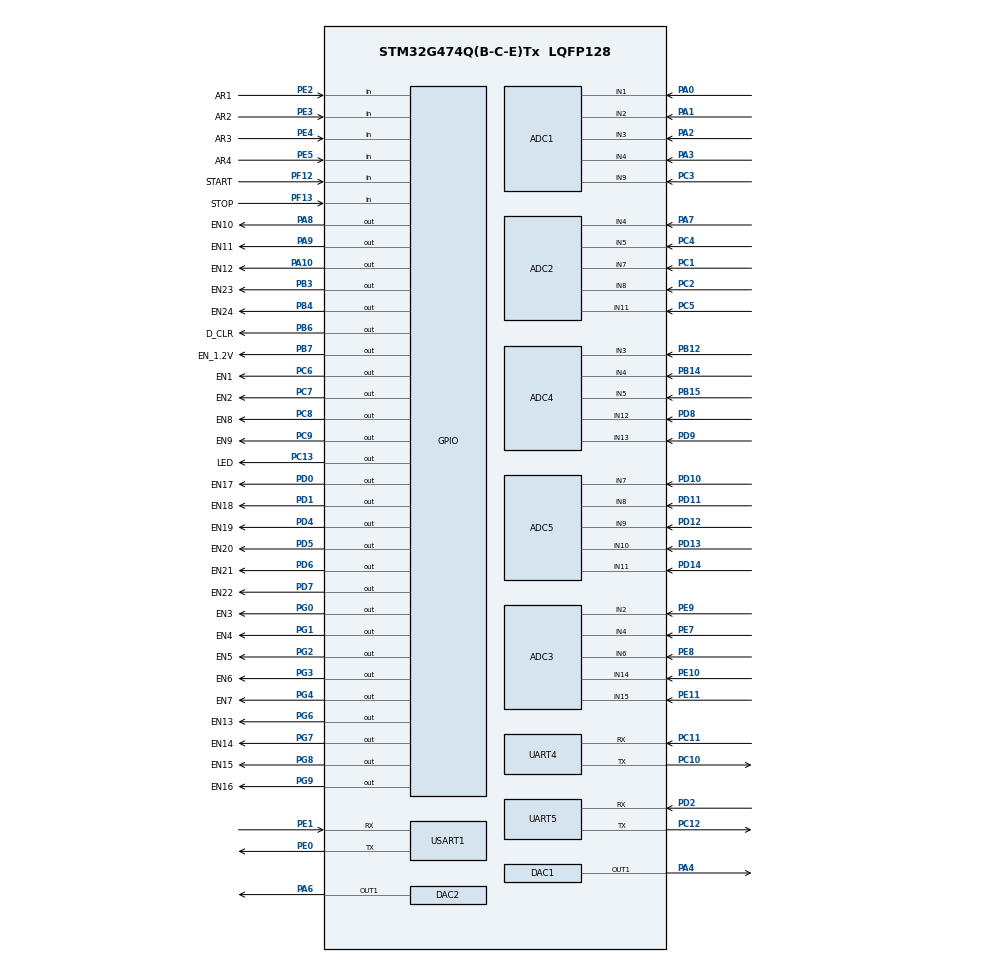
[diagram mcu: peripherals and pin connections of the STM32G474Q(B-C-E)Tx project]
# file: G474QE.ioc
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ADC1.Channel-0\#ChannelRegularConversion=ADC_CHANNEL_9
ADC1.ClockPrescaler=ADC_CLOCK_ASYNC_DIV4
ADC1.NbrOfConversionFlag=1
ADC1.OffsetNumber-0\#ChannelRegularConversion=ADC_OFFSET_NONE
ADC1.Rank-0\#ChannelRegularConversion=1
ADC1.SamplingTime-0\#ChannelRegularConversion=ADC_SAMPLETIME_2CYCLES_5
ADC1.master=1
ADC2.Channel-0\#ChannelRegularConversion=ADC_CHANNEL_4
ADC2.ClockPrescaler=ADC_CLOCK_ASYNC_DIV4
ADC2.NbrOfConversionFlag=1
ADC2.OffsetNumber-0\#ChannelRegularConversion=ADC_OFFSET_NONE
ADC2.Rank-0\#ChannelRegularConversion=1
ADC2.SamplingTime-0\#ChannelRegularConversion=ADC_SAMPLETIME_2CYCLES_5
ADC3.Channel-0\#ChannelRegularConversion=ADC_CHANNEL_4
ADC3.ClockPrescaler=ADC_CLOCK_ASYNC_DIV4
ADC3.NbrOfConversionFlag=1
ADC3.OffsetNumber-0\#ChannelRegularConversion=ADC_OFFSET_NONE
ADC3.Rank-0\#ChannelRegularConversion=1
ADC3.SamplingTime-0\#ChannelRegularConversion=ADC_SAMPLETIME_2CYCLES_5
ADC3.master=1
ADC4.Channel-1\#ChannelRegularConversion=ADC_CHANNEL_5
ADC4.ClockPrescaler=ADC_CLOCK_ASYNC_DIV4
ADC4.NbrOfConversionFlag=1
ADC4.OffsetNumber-1\#ChannelRegularConversion=ADC_OFFSET_NONE
ADC4.Rank-1\#ChannelRegularConversion=1
ADC4.SamplingTime-1\#ChannelRegularConversion=ADC_SAMPLETIME_2CYCLES_5
ADC5.Channel-0\#ChannelRegularConversion=ADC_CHANNEL_10
ADC5.ClockPrescaler=ADC_CLOCK_ASYNC_DIV4
ADC5.NbrOfConversionFlag=1
ADC5.OffsetNumber-0\#ChannelRegularConversion=ADC_OFFSET_NONE
ADC5.Rank-0\#ChannelRegularConversion=1
ADC5.SamplingTime-0\#ChannelRegularConversion=ADC_SAMPLETIME_2CYCLES_5
DAC1.DAC_SampleAndHold-DAC_OUT1=DAC_SAMPLEANDHOLD_DISABLE
Dma.ADC1.0.Direction=DMA_PERIPH_TO_MEMORY
Dma.ADC1.0.EventEnable=DISABLE
Dma.ADC1.0.Instance=DMA1_Channel1
Dma.ADC1.0.MemDataAlignment=DMA_MDATAALIGN_HALFWORD
Dma.ADC1.0.MemInc=DMA_MINC_ENABLE
Dma.ADC1.0.Mode=DMA_NORMAL
Dma.ADC1.0.PeriphDataAlignment=DMA_PDATAALIGN_HALFWORD
Dma.ADC1.0.PeriphInc=DMA_PINC_DISABLE
Dma.ADC1.0.Polarity=HAL_DMAMUX_REQ_GEN_RISING
Dma.ADC1.0.Priority=DMA_PRIORITY_LOW
Dma.ADC1.0.RequestNumber=1
Dma.ADC1.0.SignalID=NONE
Dma.ADC1.0.SyncEnable=DISABLE
Dma.ADC1.0.SyncPolarity=HAL_DMAMUX_SYNC_NO_EVENT
Dma.ADC1.0.SyncRequestNumber=1
Dma.ADC1.0.SyncSignalID=NONE
Dma.ADC2.1.Direction=DMA_PERIPH_TO_MEMORY
Dma.ADC2.1.EventEnable=DISABLE
Dma.ADC2.1.Instance=DMA1_Channel2
Dma.ADC2.1.MemDataAlignment=DMA_MDATAALIGN_HALFWORD
Dma.ADC2.1.MemInc=DMA_MINC_ENABLE
Dma.ADC2.1.Mode=DMA_NORMAL
Dma.ADC2.1.PeriphDataAlignment=DMA_PDATAALIGN_HALFWORD
Dma.ADC2.1.PeriphInc=DMA_PINC_DISABLE
Dma.ADC2.1.Polarity=HAL_DMAMUX_REQ_GEN_RISING
Dma.ADC2.1.Priority=DMA_PRIORITY_LOW
Dma.ADC2.1.RequestNumber=1
Dma.ADC2.1.SignalID=NONE
Dma.ADC2.1.SyncEnable=DISABLE
Dma.ADC2.1.SyncPolarity=HAL_DMAMUX_SYNC_NO_EVENT
Dma.ADC2.1.SyncRequestNumber=1
Dma.ADC2.1.SyncSignalID=NONE
Dma.ADC3.2.Direction=DMA_PERIPH_TO_MEMORY
Dma.ADC3.2.EventEnable=DISABLE
Dma.ADC3.2.Instance=DMA1_Channel3
Dma.ADC3.2.MemDataAlignment=DMA_MDATAALIGN_HALFWORD
Dma.ADC3.2.MemInc=DMA_MINC_ENABLE
Dma.ADC3.2.Mode=DMA_NORMAL
Dma.ADC3.2.PeriphDataAlignment=DMA_PDATAALIGN_HALFWORD
Dma.ADC3.2.PeriphInc=DMA_PINC_DISABLE
Dma.ADC3.2.Polarity=HAL_DMAMUX_REQ_GEN_RISING
Dma.ADC3.2.Priority=DMA_PRIORITY_LOW
Dma.ADC3.2.RequestNumber=1
Dma.ADC3.2.SignalID=NONE
Dma.ADC3.2.SyncEnable=DISABLE
Dma.ADC3.2.SyncPolarity=HAL_DMAMUX_SYNC_NO_EVENT
Dma.ADC3.2.SyncRequestNumber=1
Dma.ADC3.2.SyncSignalID=NONE
Dma.ADC4.3.Direction=DMA_PERIPH_TO_MEMORY
Dma.ADC4.3.EventEnable=DISABLE
Dma.ADC4.3.Instance=DMA1_Channel4
Dma.ADC4.3.MemDataAlignment=DMA_MDATAALIGN_HALFWORD
Dma.ADC4.3.MemInc=DMA_MINC_ENABLE
Dma.ADC4.3.Mode=DMA_NORMAL
Dma.ADC4.3.PeriphDataAlignment=DMA_PDATAALIGN_HALFWORD
Dma.ADC4.3.PeriphInc=DMA_PINC_DISABLE
Dma.ADC4.3.Polarity=HAL_DMAMUX_REQ_GEN_RISING
Dma.ADC4.3.Priority=DMA_PRIORITY_LOW
Dma.ADC4.3.RequestNumber=1
Dma.ADC4.3.SignalID=NONE
Dma.ADC4.3.SyncEnable=DISABLE
Dma.ADC4.3.SyncPolarity=HAL_DMAMUX_SYNC_NO_EVENT
Dma.ADC4.3.SyncRequestNumber=1
Dma.ADC4.3.SyncSignalID=NONE
Dma.ADC5.4.Direction=DMA_PERIPH_TO_MEMORY
Dma.ADC5.4.EventEnable=DISABLE
Dma.ADC5.4.Instance=DMA1_Channel5
Dma.ADC5.4.MemDataAlignment=DMA_MDATAALIGN_HALFWORD
Dma.ADC5.4.MemInc=DMA_MINC_ENABLE
Dma.ADC5.4.Mode=DMA_NORMAL
Dma.ADC5.4.PeriphDataAlignment=DMA_PDATAALIGN_HALFWORD
Dma.ADC5.4.PeriphInc=DMA_PINC_DISABLE
Dma.ADC5.4.Polarity=HAL_DMAMUX_REQ_GEN_RISING
Dma.ADC5.4.Priority=DMA_PRIORITY_LOW
Dma.ADC5.4.RequestNumber=1
Dma.ADC5.4.SignalID=NONE
Dma.ADC5.4.SyncEnable=DISABLE
Dma.ADC5.4.SyncPolarity=HAL_DMAMUX_SYNC_NO_EVENT
Dma.ADC5.4.SyncRequestNumber=1
Dma.ADC5.4.SyncSignalID=NONE
Dma.Request0=ADC1
Dma.Request1=ADC2
Dma.Request2=ADC3
Dma.Request3=ADC4
Dma.Request4=ADC5
IWDG.Prescaler=IWDG_PRESCALER_64
Mcu.Family=STM32G4
Mcu.Name=STM32G474Q(B-C-E)Tx
Mcu.Package=LQFP128
NVIC.DMA1_Channel1_IRQn=true\:0\:0\:true\:false\:true\:false\:true\:true
NVIC.DMA1_Channel2_IRQn=true\:0\:0\:false\:false\:true\:false\:true\:true
NVIC.DMA1_Channel3_IRQn=true\:0\:0\:false\:false\:true\:false\:true\:true
NVIC.DMA1_Channel4_IRQn=true\:0\:0\:false\:false\:true\:false\:true\:true
NVIC.DMA1_Channel5_IRQn=true\:0\:0\:false\:false\:true\:false\:true\:true
NVIC.PriorityGroup=NVIC_PRIORITYGROUP_4
NVIC.UART4_IRQn=true\:9\:0\:true\:false\:true\:true\:true\:true
NVIC.UART5_IRQn=true\:8\:0\:true\:false\:true\:true\:true\:true
PA0.Mode=IN1-Single-Ended
PA0.Signal=ADC1_IN1
PA1.Mode=IN2-Single-Ended
PA1.Signal=ADC1_IN2
PA10.GPIO_Label=EN12
PA10.Signal=GPIO_Output
PA13.Mode=Serial_Wire
PA13.Signal=SYS_JTMS-SWDIO
PA14.Mode=Serial_Wire
PA14.Signal=SYS_JTCK-SWCLK
PA2.Mode=IN3-Single-Ended
PA2.Signal=ADC1_IN3
PA3.Mode=IN4-Single-Ended
PA3.Signal=ADC1_IN4
PA4.Signal=COMP_DAC11_group
PA6.Signal=COMP_DAC21_group
PA7.Mode=IN4-Single-Ended
PA7.Signal=ADC2_IN4
PA8.GPIO_Label=EN10
PA8.Signal=GPIO_Output
PA9.GPIO_Label=EN11
PA9.Signal=GPIO_Output
PB12.Mode=IN3-Single-Ended
PB12.Signal=ADC4_IN3
PB14.Mode=IN4-Single-Ended
PB14.Signal=ADC4_IN4
PB15.Mode=IN5-Single-Ended
PB15.Signal=ADC4_IN5
PB3.GPIO_Label=EN23
PB3.Signal=GPIO_Output
PB4.GPIO_Label=EN24
PB4.Signal=GPIO_Output
PB6.GPIO_Label=D_CLR
PB6.Signal=GPIO_Output
PB7.GPIO_Label=EN_1.2V
PB7.Signal=GPIO_Output
PC1.Mode=IN7-Single-Ended
PC1.Signal=ADC2_IN7
PC10.Mode=Asynchronous
PC10.Signal=UART4_TX
PC11.Mode=Asynchronous
PC11.Signal=UART4_RX
PC12.Mode=Asynchronous
PC12.Signal=UART5_TX
PC13.GPIO_Label=LED
PC13.Signal=GPIO_Output
PC2.Mode=IN8-Single-Ended
PC2.Signal=ADC2_IN8
PC3.Mode=IN9-Single-Ended
PC3.Signal=ADC1_IN9
PC4.Mode=IN5-Single-Ended
PC4.Signal=ADC2_IN5
PC5.Mode=IN11-Single-Ended
PC5.Signal=ADC2_IN11
PC6.GPIO_Label=EN1
PC6.Signal=GPIO_Output
PC7.GPIO_Label=EN2
PC7.Signal=GPIO_Output
PC8.GPIO_Label=EN8
PC8.Signal=GPIO_Output
PC9.GPIO_Label=EN9
PC9.Signal=GPIO_Output
PD0.GPIO_Label=EN17
PD0.Signal=GPIO_Output
PD1.GPIO_Label=EN18
PD1.Signal=GPIO_Output
PD10.Mode=IN7-Single-Ended
PD10.Signal=ADC5_IN7
PD11.Mode=IN8-Single-Ended
PD11.Signal=ADC5_IN8
PD12.Mode=IN9-Single-Ended
PD12.Signal=ADC5_IN9
PD13.Mode=IN10-Single-Ended
PD13.Signal=ADC5_IN10
PD14.Mode=IN11-Single-Ended
PD14.Signal=ADC5_IN11
PD2.Mode=Asynchronous
PD2.Signal=UART5_RX
PD4.GPIO_Label=EN19
PD4.Signal=GPIO_Output
PD5.GPIO_Label=EN20
PD5.Signal=GPIO_Output
PD6.GPIO_Label=EN21
PD6.Signal=GPIO_Output
PD7.GPIO_Label=EN22
PD7.Signal=GPIO_Output
PD8.Mode=IN12-Single-Ended
PD8.Signal=ADC4_IN12
PD9.Mode=IN13-Single-Ended
PD9.Signal=ADC4_IN13
PE0.Mode=Asynchronous
PE0.Signal=USART1_TX
PE1.Mode=Asynchronous
PE1.Signal=USART1_RX
PE10.Mode=IN14-Single-Ended
PE10.Signal=ADC3_IN14
PE11.Mode=IN15-Single-Ended
PE11.Signal=ADC3_IN15
PE2.GPIO_Label=AR1
PE2.GPIO_Mode=GPIO_MODE_INPUT
PE2.GPIO_PuPd=GPIO_PULLUP
PE2.Signal=GPIO_Input
PE3.GPIO_Label=AR2
PE3.GPIO_Mode=GPIO_MODE_INPUT
PE3.GPIO_PuPd=GPIO_PULLUP
PE3.Signal=GPIO_Input
PE4.GPIO_Label=AR3
PE4.GPIO_Mode=GPIO_MODE_INPUT
PE4.GPIO_PuPd=GPIO_PULLUP
PE4.Signal=GPIO_Input
PE5.GPIO_Label=AR4
PE5.GPIO_Mode=GPIO_MODE_INPUT
PE5.GPIO_PuPd=GPIO_PULLUP
PE5.Signal=GPIO_Input
PE7.Mode=IN4-Single-Ended
PE7.Signal=ADC3_IN4
PE8.Mode=IN6-Single-Ended
PE8.Signal=ADC3_IN6
PE9.Mode=IN2-Single-Ended
PE9.Signal=ADC3_IN2
PF0-OSC_IN.Mode=HSE-External-Oscillator
PF0-OSC_IN.Signal=RCC_OSC_IN
PF1-OSC_OUT.Mode=HSE-External-Oscillator
PF1-OSC_OUT.Signal=RCC_OSC_OUT
PF12.GPIO_Label=START
PF12.GPIO_PuPd=GPIO_PULLUP
PF12.Signal=GPIO_Input
PF13.GPIO_Label=STOP
PF13.GPIO_PuPd=GPIO_PULLUP
PF13.Signal=GPIO_Input
PG0.GPIO_Label=EN3
PG0.Signal=GPIO_Output
PG1.GPIO_Label=EN4
PG1.Signal=GPIO_Output
PG2.GPIO_Label=EN5
PG2.Signal=GPIO_Output
PG3.GPIO_Label=EN6
PG3.Signal=GPIO_Output
PG4.GPIO_Label=EN7
PG4.Signal=GPIO_Output
PG6.GPIO_Label=EN13
PG6.PinState=GPIO_PIN_RESET
PG6.Signal=GPIO_Output
PG7.GPIO_Label=EN14
PG7.PinState=GPIO_PIN_RESET
PG7.Signal=GPIO_Output
PG8.GPIO_Label=EN15
PG8.PinState=GPIO_PIN_RESET
PG8.Signal=GPIO_Output
PG9.GPIO_Label=EN16
PG9.Signal=GPIO_Output
ProjectManager.HeapSize=0x200
ProjectManager.StackSize=0x400
ProjectManager.TargetToolchain=MDK-ARM V5.32
RCC.ADC12Freq_Value=168000000
RCC.ADC345Freq_Value=168000000
RCC.AHBFreq_Value=168000000
RCC.APB1Freq_Value=168000000
RCC.APB1TimFreq_Value=168000000
RCC.APB2Freq_Value=168000000
RCC.APB2TimFreq_Value=168000000
RCC.CortexFreq_Value=168000000
RCC.DATA_CACHE_ENABLE=0
RCC.EXTERNAL_CLOCK_VALUE=12288000
RCC.HCLKFreq_Value=168000000
RCC.HSE_VALUE=16000000
RCC.HSI48_VALUE=48000000
RCC.HSI_VALUE=16000000
RCC.INSTRUCTION_CACHE_ENABLE=0
RCC.LSE_VALUE=32768
RCC.PLLM=RCC_PLLM_DIV2
RCC.PLLN=42
RCC.PLLSourceVirtual=RCC_PLLSOURCE_HSE
RCC.SYSCLKFreq_VALUE=168000000
RCC.SYSCLKSource=RCC_SYSCLKSOURCE_PLLCLK
RCC.USBFreq_Value=168000000
RCC.VCOOutputFreq_Value=336000000
SH.COMP_DAC11_group.0=DAC1_OUT1,DAC_OUT1
SH.COMP_DAC21_group.0=DAC2_OUT1,DAC_OUT1
TIM1.Prescaler=1680-1
USART1.VirtualMode-Asynchronous=VM_ASYNC
VP_IWDG_VS_IWDG.Mode=IWDG_Activate
VP_SYS_VS_DBSignals.Mode=DisableDeadBatterySignals
VP_TIM1_VS_ClockSourceINT.Mode=Internal
VP_TIM2_VS_ClockSourceINT.Mode=Internal
VP_TIM3_VS_ClockSourceINT.Mode=Internal
board=custom

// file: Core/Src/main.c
/* USER CODE BEGIN Header */
/**
  ******************************************************************************
  * @file           : main.c
  * @brief          : Main program body
  ******************************************************************************
  * @attention
  *
  * Copyright (c) 2026 STMicroelectronics.
  * All rights reserved.
  *
  * This software is licensed under terms that can be found in the LICENSE file
  * in the root directory of this software component.
  * If no LICENSE file comes with this software, it is provided AS-IS.
  *
  ******************************************************************************
  */
/* USER CODE END Header */
#include "main.h"

/* USER CODE BEGIN Includes */
#define 	ADC_SAMPLE_TIME						LL_ADC_SAMPLINGTIME_24CYCLES_5
/* USER CODE END Includes */

void SystemClock_Config(void);
static void MX_GPIO_Init(void);
static void MX_DMA_Init(void);
static void MX_ADC1_Init(void);
static void MX_ADC2_Init(void);
static void MX_ADC3_Init(void);
static void MX_ADC4_Init(void);
static void MX_ADC5_Init(void);
static void MX_DAC1_Init(void);
static void MX_DAC2_Init(void);
static void MX_USART1_UART_Init(void);
static void MX_UART4_Init(void);
static void MX_UART5_Init(void);
static void MX_TIM1_Init(void);
static void MX_TIM2_Init(void);
static void MX_TIM3_Init(void);
static void MX_IWDG_Init(void);
/* USER CODE BEGIN PFP */
void Activate_ADC(ADC_TypeDef *ADCx);

/* USER CODE END PFP */

int main(void)
{

  /* MCU Configuration--------------------------------------------------------*/

  /* Reset of all peripherals, Initializes the Flash interface and the Systick. */
  LL_APB2_GRP1_EnableClock(LL_APB2_GRP1_PERIPH_SYSCFG);
  LL_APB1_GRP1_EnableClock(LL_APB1_GRP1_PERIPH_PWR);

  /* System interrupt init*/
  NVIC_SetPriorityGrouping(NVIC_PRIORITYGROUP_4);

  /* SysTick_IRQn interrupt configuration */
  NVIC_SetPriority(SysTick_IRQn, NVIC_EncodePriority(NVIC_GetPriorityGrouping(),10, 0));

  /** Disable the internal Pull-Up in Dead Battery pins of UCPD peripheral
  */
  LL_PWR_DisableUCPDDeadBattery();

  /* Configure the system clock */
  SystemClock_Config();

  /* USER CODE BEGIN SysInit */
	initUartFifo();

  /* USER CODE END SysInit */

  /* Initialize all configured peripherals */
  MX_GPIO_Init();
  MX_DMA_Init();
  MX_ADC1_Init();
  MX_ADC2_Init();
  MX_ADC3_Init();
  MX_ADC4_Init();
  MX_ADC5_Init();
  MX_DAC1_Init();
  MX_DAC2_Init();
  MX_USART1_UART_Init();
  MX_UART4_Init();
  MX_UART5_Init();
  MX_TIM1_Init();
  MX_TIM2_Init();
  MX_TIM3_Init();
  //MX_IWDG_Init();
  /* USER CODE BEGIN 2 */
	readMyAddr();
 Activate_ADC(ADC1);
 Activate_ADC(ADC2);
 Activate_ADC(ADC3);
 Activate_ADC(ADC4);
 Activate_ADC(ADC5);
 initADC();

  Trace_Print(" system start \r\n");
  /* USER CODE END 2 */

  /* Infinite loop */
  /* USER CODE BEGIN WHILE */
  while (1)
  {

 	  cleanMain();
		debugFunc();
   // testuart4Send();
		//testuart5Send();
    /* USER CODE END WHILE */

  }
}

void SystemClock_Config(void)
{
  LL_FLASH_SetLatency(LL_FLASH_LATENCY_4);
  while(LL_FLASH_GetLatency() != LL_FLASH_LATENCY_4)
  {
  }
  LL_PWR_EnableRange1BoostMode();
  LL_RCC_HSE_Enable();
   /* Wait till HSE is ready */
  while(LL_RCC_HSE_IsReady() != 1)
  {
  }

  LL_RCC_LSI_Enable();
   /* Wait till LSI is ready */
  while(LL_RCC_LSI_IsReady() != 1)
  {
  }

  LL_RCC_PLL_ConfigDomain_SYS(LL_RCC_PLLSOURCE_HSE, LL_RCC_PLLM_DIV_2, 42, LL_RCC_PLLR_DIV_2);
  LL_RCC_PLL_EnableDomain_SYS();
  LL_RCC_PLL_Enable();
   /* Wait till PLL is ready */
  while(LL_RCC_PLL_IsReady() != 1)
  {
  }

  LL_RCC_SetSysClkSource(LL_RCC_SYS_CLKSOURCE_PLL);
  LL_RCC_SetAHBPrescaler(LL_RCC_SYSCLK_DIV_2);
   /* Wait till System clock is ready */
  while(LL_RCC_GetSysClkSource() != LL_RCC_SYS_CLKSOURCE_STATUS_PLL)
  {
  }

  /* Insure 1us transition state at intermediate medium speed clock*/
  for (__IO uint32_t i = (170 >> 1); i !=0; i--);

  /* Set AHB prescaler*/
  LL_RCC_SetAHBPrescaler(LL_RCC_SYSCLK_DIV_1);
  LL_RCC_SetAPB1Prescaler(LL_RCC_APB1_DIV_1);
  LL_RCC_SetAPB2Prescaler(LL_RCC_APB2_DIV_1);

  LL_Init1msTick(168000000);

  LL_SetSystemCoreClock(168000000);
}

static void MX_ADC1_Init(void)
{

  LL_ADC_InitTypeDef ADC_InitStruct = {0};
  LL_ADC_REG_InitTypeDef ADC_REG_InitStruct = {0};
  LL_ADC_CommonInitTypeDef ADC_CommonInitStruct = {0};

  LL_GPIO_InitTypeDef GPIO_InitStruct = {0};

  LL_RCC_SetADCClockSource(LL_RCC_ADC12_CLKSOURCE_SYSCLK);

  /* Peripheral clock enable */
  LL_AHB2_GRP1_EnableClock(LL_AHB2_GRP1_PERIPH_ADC12);

  LL_AHB2_GRP1_EnableClock(LL_AHB2_GRP1_PERIPH_GPIOC);
  LL_AHB2_GRP1_EnableClock(LL_AHB2_GRP1_PERIPH_GPIOA);
  /**ADC1 GPIO Configuration
  PC3   ------> ADC1_IN9
  PA0   ------> ADC1_IN1
  PA1   ------> ADC1_IN2
  PA2   ------> ADC1_IN3
  PA3   ------> ADC1_IN4
  */
  GPIO_InitStruct.Pin = LL_GPIO_PIN_3;
  GPIO_InitStruct.Mode = LL_GPIO_MODE_ANALOG;
  GPIO_InitStruct.Pull = LL_GPIO_PULL_NO;
  LL_GPIO_Init(GPIOC, &GPIO_InitStruct);

  GPIO_InitStruct.Pin = LL_GPIO_PIN_0;
  GPIO_InitStruct.Mode = LL_GPIO_MODE_ANALOG;
  GPIO_InitStruct.Pull = LL_GPIO_PULL_NO;
  LL_GPIO_Init(GPIOA, &GPIO_InitStruct);

  GPIO_InitStruct.Pin = LL_GPIO_PIN_1;
  GPIO_InitStruct.Mode = LL_GPIO_MODE_ANALOG;
  GPIO_InitStruct.Pull = LL_GPIO_PULL_NO;
  LL_GPIO_Init(GPIOA, &GPIO_InitStruct);

  GPIO_InitStruct.Pin = LL_GPIO_PIN_2;
  GPIO_InitStruct.Mode = LL_GPIO_MODE_ANALOG;
  GPIO_InitStruct.Pull = LL_GPIO_PULL_NO;
  LL_GPIO_Init(GPIOA, &GPIO_InitStruct);

  GPIO_InitStruct.Pin = LL_GPIO_PIN_3;
  GPIO_InitStruct.Mode = LL_GPIO_MODE_ANALOG;
  GPIO_InitStruct.Pull = LL_GPIO_PULL_NO;
  LL_GPIO_Init(GPIOA, &GPIO_InitStruct);

  /* ADC1 DMA Init */

  /* ADC1 Init */
  LL_DMA_SetPeriphRequest(DMA1, LL_DMA_CHANNEL_1, LL_DMAMUX_REQ_ADC1);

  LL_DMA_SetDataTransferDirection(DMA1, LL_DMA_CHANNEL_1, LL_DMA_DIRECTION_PERIPH_TO_MEMORY);

  LL_DMA_SetChannelPriorityLevel(DMA1, LL_DMA_CHANNEL_1, LL_DMA_PRIORITY_LOW);

  LL_DMA_SetMode(DMA1, LL_DMA_CHANNEL_1, LL_DMA_MODE_NORMAL);

  LL_DMA_SetPeriphIncMode(DMA1, LL_DMA_CHANNEL_1, LL_DMA_PERIPH_NOINCREMENT);

  LL_DMA_SetMemoryIncMode(DMA1, LL_DMA_CHANNEL_1, LL_DMA_MEMORY_INCREMENT);

  LL_DMA_SetPeriphSize(DMA1, LL_DMA_CHANNEL_1, LL_DMA_PDATAALIGN_HALFWORD);

  LL_DMA_SetMemorySize(DMA1, LL_DMA_CHANNEL_1, LL_DMA_MDATAALIGN_HALFWORD);

  /** Common config
  */
  ADC_InitStruct.Resolution = LL_ADC_RESOLUTION_12B;
  ADC_InitStruct.DataAlignment = LL_ADC_DATA_ALIGN_RIGHT;
  ADC_InitStruct.LowPowerMode = LL_ADC_LP_MODE_NONE;
  LL_ADC_Init(ADC1, &ADC_InitStruct);
  ADC_REG_InitStruct.TriggerSource = LL_ADC_REG_TRIG_SOFTWARE;
  ADC_REG_InitStruct.SequencerLength = LL_ADC_REG_SEQ_SCAN_ENABLE_5RANKS;
  ADC_REG_InitStruct.SequencerDiscont = LL_ADC_REG_SEQ_DISCONT_DISABLE;
  ADC_REG_InitStruct.ContinuousMode = LL_ADC_REG_CONV_CONTINUOUS;
  ADC_REG_InitStruct.DMATransfer = LL_ADC_REG_DMA_TRANSFER_UNLIMITED;
  ADC_REG_InitStruct.Overrun = LL_ADC_REG_OVR_DATA_PRESERVED;
  LL_ADC_REG_Init(ADC1, &ADC_REG_InitStruct);
  LL_ADC_SetGainCompensation(ADC1, 0);
  LL_ADC_SetOverSamplingScope(ADC1, LL_ADC_OVS_DISABLE);
  ADC_CommonInitStruct.CommonClock = LL_ADC_CLOCK_ASYNC_DIV16;
  ADC_CommonInitStruct.Multimode = LL_ADC_MULTI_INDEPENDENT;
  LL_ADC_CommonInit(__LL_ADC_COMMON_INSTANCE(ADC1), &ADC_CommonInitStruct);

  /* Disable ADC deep power down (enabled by default after reset state) */
  LL_ADC_DisableDeepPowerDown(ADC1);
  /* Enable ADC internal voltage regulator */
  LL_ADC_EnableInternalRegulator(ADC1);
  /* Delay for ADC internal voltage regulator stabilization. */
  /* Compute number of CPU cycles to wait for, from delay in us. */
  /* Note: Variable divided by 2 to compensate partially */
  /* CPU processing cycles (depends on compilation optimization). */
  /* Note: If system core clock frequency is below 200kHz, wait time */
  /* is only a few CPU processing cycles. */
  uint32_t wait_loop_index;
  wait_loop_index = ((LL_ADC_DELAY_INTERNAL_REGUL_STAB_US * (SystemCoreClock / (100000 * 2))) / 10);
  while(wait_loop_index != 0)
  {
    wait_loop_index--;
  }

  /** Configure Regular Channel
  */
  /* USER CODE BEGIN ADC1_Init 2 */

	// 18 -22
  LL_ADC_REG_SetSequencerRanks(ADC1, LL_ADC_REG_RANK_1, LL_ADC_CHANNEL_4);
  LL_ADC_SetChannelSamplingTime(ADC1, LL_ADC_CHANNEL_4, ADC_SAMPLE_TIME);
  LL_ADC_SetChannelSingleDiff(ADC1, LL_ADC_CHANNEL_4, LL_ADC_SINGLE_ENDED);

  LL_ADC_REG_SetSequencerRanks(ADC1, LL_ADC_REG_RANK_2, LL_ADC_CHANNEL_3);
  LL_ADC_SetChannelSamplingTime(ADC1, LL_ADC_CHANNEL_3, ADC_SAMPLE_TIME);
  LL_ADC_SetChannelSingleDiff(ADC1, LL_ADC_CHANNEL_3, LL_ADC_SINGLE_ENDED);

  LL_ADC_REG_SetSequencerRanks(ADC1, LL_ADC_REG_RANK_3, LL_ADC_CHANNEL_2);
  LL_ADC_SetChannelSamplingTime(ADC1, LL_ADC_CHANNEL_2, ADC_SAMPLE_TIME);
  LL_ADC_SetChannelSingleDiff(ADC1, LL_ADC_CHANNEL_2, LL_ADC_SINGLE_ENDED);

  LL_ADC_REG_SetSequencerRanks(ADC1, LL_ADC_REG_RANK_4, LL_ADC_CHANNEL_1);
  LL_ADC_SetChannelSamplingTime(ADC1, LL_ADC_CHANNEL_1, ADC_SAMPLE_TIME);
  LL_ADC_SetChannelSingleDiff(ADC1, LL_ADC_CHANNEL_1, LL_ADC_SINGLE_ENDED);

  LL_ADC_REG_SetSequencerRanks(ADC1, LL_ADC_REG_RANK_5, LL_ADC_CHANNEL_9);
  LL_ADC_SetChannelSamplingTime(ADC1, LL_ADC_CHANNEL_9, ADC_SAMPLE_TIME);
  LL_ADC_SetChannelSingleDiff(ADC1, LL_ADC_CHANNEL_9, LL_ADC_SINGLE_ENDED);

	//LL_ADC_REG_SetSequencerLength(ADC1,LL_ADC_REG_SEQ_SCAN_ENABLE_5RANKS);
	//LL_ADC_REG_SetContinuousMode

  /* USER CODE END ADC1_Init 2 */

}

static void MX_ADC2_Init(void)
{

  LL_ADC_InitTypeDef ADC_InitStruct = {0};
  LL_ADC_REG_InitTypeDef ADC_REG_InitStruct = {0};

  LL_GPIO_InitTypeDef GPIO_InitStruct = {0};

  LL_RCC_SetADCClockSource(LL_RCC_ADC12_CLKSOURCE_SYSCLK);

  /* Peripheral clock enable */
  LL_AHB2_GRP1_EnableClock(LL_AHB2_GRP1_PERIPH_ADC12);

  LL_AHB2_GRP1_EnableClock(LL_AHB2_GRP1_PERIPH_GPIOC);
  LL_AHB2_GRP1_EnableClock(LL_AHB2_GRP1_PERIPH_GPIOA);
  /**ADC2 GPIO Configuration
  PC1   ------> ADC2_IN7
  PC2   ------> ADC2_IN8
  PA7   ------> ADC2_IN4
  PC4   ------> ADC2_IN5
  PC5   ------> ADC2_IN11
  */
  GPIO_InitStruct.Pin = LL_GPIO_PIN_1;
  GPIO_InitStruct.Mode = LL_GPIO_MODE_ANALOG;
  GPIO_InitStruct.Pull = LL_GPIO_PULL_NO;
  LL_GPIO_Init(GPIOC, &GPIO_InitStruct);

  GPIO_InitStruct.Pin = LL_GPIO_PIN_2;
  GPIO_InitStruct.Mode = LL_GPIO_MODE_ANALOG;
  GPIO_InitStruct.Pull = LL_GPIO_PULL_NO;
  LL_GPIO_Init(GPIOC, &GPIO_InitStruct);

  GPIO_InitStruct.Pin = LL_GPIO_PIN_7;
  GPIO_InitStruct.Mode = LL_GPIO_MODE_ANALOG;
  GPIO_InitStruct.Pull = LL_GPIO_PULL_NO;
  LL_GPIO_Init(GPIOA, &GPIO_InitStruct);

  GPIO_InitStruct.Pin = LL_GPIO_PIN_4;
  GPIO_InitStruct.Mode = LL_GPIO_MODE_ANALOG;
  GPIO_InitStruct.Pull = LL_GPIO_PULL_NO;
  LL_GPIO_Init(GPIOC, &GPIO_InitStruct);

  GPIO_InitStruct.Pin = LL_GPIO_PIN_5;
  GPIO_InitStruct.Mode = LL_GPIO_MODE_ANALOG;
  GPIO_InitStruct.Pull = LL_GPIO_PULL_NO;
  LL_GPIO_Init(GPIOC, &GPIO_InitStruct);

  /* ADC2 DMA Init */

  /* ADC2 Init */
  LL_DMA_SetPeriphRequest(DMA1, LL_DMA_CHANNEL_2, LL_DMAMUX_REQ_ADC2);

  LL_DMA_SetDataTransferDirection(DMA1, LL_DMA_CHANNEL_2, LL_DMA_DIRECTION_PERIPH_TO_MEMORY);

  LL_DMA_SetChannelPriorityLevel(DMA1, LL_DMA_CHANNEL_2, LL_DMA_PRIORITY_LOW);

  LL_DMA_SetMode(DMA1, LL_DMA_CHANNEL_2, LL_DMA_MODE_NORMAL);

  LL_DMA_SetPeriphIncMode(DMA1, LL_DMA_CHANNEL_2, LL_DMA_PERIPH_NOINCREMENT);

  LL_DMA_SetMemoryIncMode(DMA1, LL_DMA_CHANNEL_2, LL_DMA_MEMORY_INCREMENT);

  LL_DMA_SetPeriphSize(DMA1, LL_DMA_CHANNEL_2, LL_DMA_PDATAALIGN_HALFWORD);

  LL_DMA_SetMemorySize(DMA1, LL_DMA_CHANNEL_2, LL_DMA_MDATAALIGN_HALFWORD);

  /** Common config
  */
  ADC_InitStruct.Resolution = LL_ADC_RESOLUTION_12B;
  ADC_InitStruct.DataAlignment = LL_ADC_DATA_ALIGN_RIGHT;
  ADC_InitStruct.LowPowerMode = LL_ADC_LP_MODE_NONE;
  LL_ADC_Init(ADC2, &ADC_InitStruct);
  ADC_REG_InitStruct.TriggerSource = LL_ADC_REG_TRIG_SOFTWARE;
  ADC_REG_InitStruct.SequencerLength = LL_ADC_REG_SEQ_SCAN_ENABLE_5RANKS;
  ADC_REG_InitStruct.SequencerDiscont = LL_ADC_REG_SEQ_DISCONT_DISABLE;
  ADC_REG_InitStruct.ContinuousMode = LL_ADC_REG_CONV_CONTINUOUS;
  ADC_REG_InitStruct.DMATransfer = LL_ADC_REG_DMA_TRANSFER_UNLIMITED;
  ADC_REG_InitStruct.Overrun = LL_ADC_REG_OVR_DATA_PRESERVED;
  LL_ADC_REG_Init(ADC2, &ADC_REG_InitStruct);
  LL_ADC_SetGainCompensation(ADC2, 0);
  LL_ADC_SetOverSamplingScope(ADC2, LL_ADC_OVS_DISABLE);

  /* Disable ADC deep power down (enabled by default after reset state) */
  LL_ADC_DisableDeepPowerDown(ADC2);
  /* Enable ADC internal voltage regulator */
  LL_ADC_EnableInternalRegulator(ADC2);
  /* Delay for ADC internal voltage regulator stabilization. */
  /* Compute number of CPU cycles to wait for, from delay in us. */
  /* Note: Variable divided by 2 to compensate partially */
  /* CPU processing cycles (depends on compilation optimization). */
  /* Note: If system core clock frequency is below 200kHz, wait time */
  /* is only a few CPU processing cycles. */
  uint32_t wait_loop_index;
  wait_loop_index = ((LL_ADC_DELAY_INTERNAL_REGUL_STAB_US * (SystemCoreClock / (100000 * 2))) / 10);
  while(wait_loop_index != 0)
  {
    wait_loop_index--;
  }

  /** Configure Regular Channel
  */

  /* USER CODE BEGIN ADC2_Init 2 */
	// 15-17,23,24
  LL_ADC_REG_SetSequencerRanks(ADC2, LL_ADC_REG_RANK_1, LL_ADC_CHANNEL_11);
  LL_ADC_SetChannelSamplingTime(ADC2, LL_ADC_CHANNEL_11, ADC_SAMPLE_TIME);
  LL_ADC_SetChannelSingleDiff(ADC2, LL_ADC_CHANNEL_11, LL_ADC_SINGLE_ENDED);

  LL_ADC_REG_SetSequencerRanks(ADC2, LL_ADC_REG_RANK_2, LL_ADC_CHANNEL_5);
  LL_ADC_SetChannelSamplingTime(ADC2, LL_ADC_CHANNEL_5, ADC_SAMPLE_TIME);
  LL_ADC_SetChannelSingleDiff(ADC2, LL_ADC_CHANNEL_5, LL_ADC_SINGLE_ENDED);

  LL_ADC_REG_SetSequencerRanks(ADC2, LL_ADC_REG_RANK_3, LL_ADC_CHANNEL_4);
  LL_ADC_SetChannelSamplingTime(ADC2, LL_ADC_CHANNEL_4, ADC_SAMPLE_TIME);
  LL_ADC_SetChannelSingleDiff(ADC2, LL_ADC_CHANNEL_4, LL_ADC_SINGLE_ENDED);

	LL_ADC_REG_SetSequencerRanks(ADC2, LL_ADC_REG_RANK_4, LL_ADC_CHANNEL_8);
  LL_ADC_SetChannelSamplingTime(ADC2, LL_ADC_CHANNEL_8, ADC_SAMPLE_TIME);
  LL_ADC_SetChannelSingleDiff(ADC2, LL_ADC_CHANNEL_8, LL_ADC_SINGLE_ENDED);

	LL_ADC_REG_SetSequencerRanks(ADC2, LL_ADC_REG_RANK_5, LL_ADC_CHANNEL_7);
  LL_ADC_SetChannelSamplingTime(ADC2, LL_ADC_CHANNEL_7, ADC_SAMPLE_TIME);
  LL_ADC_SetChannelSingleDiff(ADC2, LL_ADC_CHANNEL_7, LL_ADC_SINGLE_ENDED);

	//LL_ADC_REG_SetSequencerLength(ADC2,LL_ADC_REG_SEQ_SCAN_ENABLE_5RANKS);

  /* USER CODE END ADC2_Init 2 */

}

static void MX_ADC3_Init(void)
{

  LL_ADC_InitTypeDef ADC_InitStruct = {0};
  LL_ADC_REG_InitTypeDef ADC_REG_InitStruct = {0};
  LL_ADC_CommonInitTypeDef ADC_CommonInitStruct = {0};

  LL_GPIO_InitTypeDef GPIO_InitStruct = {0};

  LL_RCC_SetADCClockSource(LL_RCC_ADC345_CLKSOURCE_SYSCLK);

  /* Peripheral clock enable */
  LL_AHB2_GRP1_EnableClock(LL_AHB2_GRP1_PERIPH_ADC345);

  LL_AHB2_GRP1_EnableClock(LL_AHB2_GRP1_PERIPH_GPIOE);
  /**ADC3 GPIO Configuration
  PE7   ------> ADC3_IN4
  PE8   ------> ADC3_IN6
  PE9   ------> ADC3_IN2
  PE10   ------> ADC3_IN14
  PE11   ------> ADC3_IN15
  */
  GPIO_InitStruct.Pin = LL_GPIO_PIN_7;
  GPIO_InitStruct.Mode = LL_GPIO_MODE_ANALOG;
  GPIO_InitStruct.Pull = LL_GPIO_PULL_NO;
  LL_GPIO_Init(GPIOE, &GPIO_InitStruct);

  GPIO_InitStruct.Pin = LL_GPIO_PIN_8;
  GPIO_InitStruct.Mode = LL_GPIO_MODE_ANALOG;
  GPIO_InitStruct.Pull = LL_GPIO_PULL_NO;
  LL_GPIO_Init(GPIOE, &GPIO_InitStruct);

  GPIO_InitStruct.Pin = LL_GPIO_PIN_9;
  GPIO_InitStruct.Mode = LL_GPIO_MODE_ANALOG;
  GPIO_InitStruct.Pull = LL_GPIO_PULL_NO;
  LL_GPIO_Init(GPIOE, &GPIO_InitStruct);

  GPIO_InitStruct.Pin = LL_GPIO_PIN_10;
  GPIO_InitStruct.Mode = LL_GPIO_MODE_ANALOG;
  GPIO_InitStruct.Pull = LL_GPIO_PULL_NO;
  LL_GPIO_Init(GPIOE, &GPIO_InitStruct);

  GPIO_InitStruct.Pin = LL_GPIO_PIN_11;
  GPIO_InitStruct.Mode = LL_GPIO_MODE_ANALOG;
  GPIO_InitStruct.Pull = LL_GPIO_PULL_NO;
  LL_GPIO_Init(GPIOE, &GPIO_InitStruct);

  /* ADC3 DMA Init */

  /* ADC3 Init */
  LL_DMA_SetPeriphRequest(DMA1, LL_DMA_CHANNEL_3, LL_DMAMUX_REQ_ADC3);

  LL_DMA_SetDataTransferDirection(DMA1, LL_DMA_CHANNEL_3, LL_DMA_DIRECTION_PERIPH_TO_MEMORY);

  LL_DMA_SetChannelPriorityLevel(DMA1, LL_DMA_CHANNEL_3, LL_DMA_PRIORITY_LOW);

  LL_DMA_SetMode(DMA1, LL_DMA_CHANNEL_3, LL_DMA_MODE_NORMAL);

  LL_DMA_SetPeriphIncMode(DMA1, LL_DMA_CHANNEL_3, LL_DMA_PERIPH_NOINCREMENT);

  LL_DMA_SetMemoryIncMode(DMA1, LL_DMA_CHANNEL_3, LL_DMA_MEMORY_INCREMENT);

  LL_DMA_SetPeriphSize(DMA1, LL_DMA_CHANNEL_3, LL_DMA_PDATAALIGN_HALFWORD);

  LL_DMA_SetMemorySize(DMA1, LL_DMA_CHANNEL_3, LL_DMA_MDATAALIGN_HALFWORD);

  /** Common config
  */
  ADC_InitStruct.Resolution = LL_ADC_RESOLUTION_12B;
  ADC_InitStruct.DataAlignment = LL_ADC_DATA_ALIGN_RIGHT;
  ADC_InitStruct.LowPowerMode = LL_ADC_LP_MODE_NONE;
  LL_ADC_Init(ADC3, &ADC_InitStruct);
  ADC_REG_InitStruct.TriggerSource = LL_ADC_REG_TRIG_SOFTWARE;
  ADC_REG_InitStruct.SequencerLength = LL_ADC_REG_SEQ_SCAN_ENABLE_5RANKS;
  ADC_REG_InitStruct.SequencerDiscont = LL_ADC_REG_SEQ_DISCONT_DISABLE;
  ADC_REG_InitStruct.ContinuousMode = LL_ADC_REG_CONV_CONTINUOUS;
  ADC_REG_InitStruct.DMATransfer = LL_ADC_REG_DMA_TRANSFER_UNLIMITED;
  ADC_REG_InitStruct.Overrun = LL_ADC_REG_OVR_DATA_PRESERVED;
  LL_ADC_REG_Init(ADC3, &ADC_REG_InitStruct);
  LL_ADC_SetGainCompensation(ADC3, 0);
  LL_ADC_SetOverSamplingScope(ADC3, LL_ADC_OVS_DISABLE);
  ADC_CommonInitStruct.CommonClock = LL_ADC_CLOCK_ASYNC_DIV16;
  ADC_CommonInitStruct.Multimode = LL_ADC_MULTI_INDEPENDENT;
  LL_ADC_CommonInit(__LL_ADC_COMMON_INSTANCE(ADC3), &ADC_CommonInitStruct);

  /* Disable ADC deep power down (enabled by default after reset state) */
  LL_ADC_DisableDeepPowerDown(ADC3);
  /* Enable ADC internal voltage regulator */
  LL_ADC_EnableInternalRegulator(ADC3);
  /* Delay for ADC internal voltage regulator stabilization. */
  /* Compute number of CPU cycles to wait for, from delay in us. */
  /* Note: Variable divided by 2 to compensate partially */
  /* CPU processing cycles (depends on compilation optimization). */
  /* Note: If system core clock frequency is below 200kHz, wait time */
  /* is only a few CPU processing cycles. */
  uint32_t wait_loop_index;
  wait_loop_index = ((LL_ADC_DELAY_INTERNAL_REGUL_STAB_US * (SystemCoreClock / (100000 * 2))) / 10);
  while(wait_loop_index != 0)
  {
    wait_loop_index--;
  }

  /** Configure Regular Channel
  */

  /* USER CODE BEGIN ADC3_Init 2 */
	// 10-14
  LL_ADC_REG_SetSequencerRanks(ADC3, LL_ADC_REG_RANK_1, LL_ADC_CHANNEL_15);
  LL_ADC_SetChannelSamplingTime(ADC3, LL_ADC_CHANNEL_15, ADC_SAMPLE_TIME);
  LL_ADC_SetChannelSingleDiff(ADC3, LL_ADC_CHANNEL_15, LL_ADC_SINGLE_ENDED);

  LL_ADC_REG_SetSequencerRanks(ADC3, LL_ADC_REG_RANK_2, LL_ADC_CHANNEL_14);
  LL_ADC_SetChannelSamplingTime(ADC3, LL_ADC_CHANNEL_14, ADC_SAMPLE_TIME);
  LL_ADC_SetChannelSingleDiff(ADC3, LL_ADC_CHANNEL_14, LL_ADC_SINGLE_ENDED);

  LL_ADC_REG_SetSequencerRanks(ADC3, LL_ADC_REG_RANK_3, LL_ADC_CHANNEL_2);
  LL_ADC_SetChannelSamplingTime(ADC3, LL_ADC_CHANNEL_2, ADC_SAMPLE_TIME);
  LL_ADC_SetChannelSingleDiff(ADC3, LL_ADC_CHANNEL_2, LL_ADC_SINGLE_ENDED);

	LL_ADC_REG_SetSequencerRanks(ADC3, LL_ADC_REG_RANK_4, LL_ADC_CHANNEL_6);
  LL_ADC_SetChannelSamplingTime(ADC3, LL_ADC_CHANNEL_6, ADC_SAMPLE_TIME);
  LL_ADC_SetChannelSingleDiff(ADC3, LL_ADC_CHANNEL_6, LL_ADC_SINGLE_ENDED);

  LL_ADC_REG_SetSequencerRanks(ADC3, LL_ADC_REG_RANK_5, LL_ADC_CHANNEL_4);
  LL_ADC_SetChannelSamplingTime(ADC3, LL_ADC_CHANNEL_4, ADC_SAMPLE_TIME);
  LL_ADC_SetChannelSingleDiff(ADC3, LL_ADC_CHANNEL_4, LL_ADC_SINGLE_ENDED);

	//LL_ADC_REG_SetSequencerLength(ADC3,LL_ADC_REG_SEQ_SCAN_ENABLE_5RANKS);

  /* USER CODE END ADC3_Init 2 */

}

static void MX_ADC4_Init(void)
{

  LL_ADC_InitTypeDef ADC_InitStruct = {0};
  LL_ADC_REG_InitTypeDef ADC_REG_InitStruct = {0};

  LL_GPIO_InitTypeDef GPIO_InitStruct = {0};

  LL_RCC_SetADCClockSource(LL_RCC_ADC345_CLKSOURCE_SYSCLK);

  /* Peripheral clock enable */
  LL_AHB2_GRP1_EnableClock(LL_AHB2_GRP1_PERIPH_ADC345);

  LL_AHB2_GRP1_EnableClock(LL_AHB2_GRP1_PERIPH_GPIOB);
  LL_AHB2_GRP1_EnableClock(LL_AHB2_GRP1_PERIPH_GPIOD);
  /**ADC4 GPIO Configuration
  PB12   ------> ADC4_IN3
  PB14   ------> ADC4_IN4
  PB15   ------> ADC4_IN5
  PD8   ------> ADC4_IN12
  PD9   ------> ADC4_IN13
  */
  GPIO_InitStruct.Pin = LL_GPIO_PIN_12;
  GPIO_InitStruct.Mode = LL_GPIO_MODE_ANALOG;
  GPIO_InitStruct.Pull = LL_GPIO_PULL_NO;
  LL_GPIO_Init(GPIOB, &GPIO_InitStruct);

  GPIO_InitStruct.Pin = LL_GPIO_PIN_14;
  GPIO_InitStruct.Mode = LL_GPIO_MODE_ANALOG;
  GPIO_InitStruct.Pull = LL_GPIO_PULL_NO;
  LL_GPIO_Init(GPIOB, &GPIO_InitStruct);

  GPIO_InitStruct.Pin = LL_GPIO_PIN_15;
  GPIO_InitStruct.Mode = LL_GPIO_MODE_ANALOG;
  GPIO_InitStruct.Pull = LL_GPIO_PULL_NO;
  LL_GPIO_Init(GPIOB, &GPIO_InitStruct);

  GPIO_InitStruct.Pin = LL_GPIO_PIN_8;
  GPIO_InitStruct.Mode = LL_GPIO_MODE_ANALOG;
  GPIO_InitStruct.Pull = LL_GPIO_PULL_NO;
  LL_GPIO_Init(GPIOD, &GPIO_InitStruct);

  GPIO_InitStruct.Pin = LL_GPIO_PIN_9;
  GPIO_InitStruct.Mode = LL_GPIO_MODE_ANALOG;
  GPIO_InitStruct.Pull = LL_GPIO_PULL_NO;
  LL_GPIO_Init(GPIOD, &GPIO_InitStruct);

  /* ADC4 DMA Init */

  /* ADC4 Init */
  LL_DMA_SetPeriphRequest(DMA1, LL_DMA_CHANNEL_4, LL_DMAMUX_REQ_ADC4);

  LL_DMA_SetDataTransferDirection(DMA1, LL_DMA_CHANNEL_4, LL_DMA_DIRECTION_PERIPH_TO_MEMORY);

  LL_DMA_SetChannelPriorityLevel(DMA1, LL_DMA_CHANNEL_4, LL_DMA_PRIORITY_LOW);

  LL_DMA_SetMode(DMA1, LL_DMA_CHANNEL_4, LL_DMA_MODE_NORMAL);

  LL_DMA_SetPeriphIncMode(DMA1, LL_DMA_CHANNEL_4, LL_DMA_PERIPH_NOINCREMENT);

  LL_DMA_SetMemoryIncMode(DMA1, LL_DMA_CHANNEL_4, LL_DMA_MEMORY_INCREMENT);

  LL_DMA_SetPeriphSize(DMA1, LL_DMA_CHANNEL_4, LL_DMA_PDATAALIGN_HALFWORD);

  LL_DMA_SetMemorySize(DMA1, LL_DMA_CHANNEL_4, LL_DMA_MDATAALIGN_HALFWORD);

  /** Common config
  */
  ADC_InitStruct.Resolution = LL_ADC_RESOLUTION_12B;
  ADC_InitStruct.DataAlignment = LL_ADC_DATA_ALIGN_RIGHT;
  ADC_InitStruct.LowPowerMode = LL_ADC_LP_MODE_NONE;
  LL_ADC_Init(ADC4, &ADC_InitStruct);
  ADC_REG_InitStruct.TriggerSource = LL_ADC_REG_TRIG_SOFTWARE;
  ADC_REG_InitStruct.SequencerLength = LL_ADC_REG_SEQ_SCAN_ENABLE_5RANKS;
  ADC_REG_InitStruct.SequencerDiscont = LL_ADC_REG_SEQ_DISCONT_DISABLE;
  ADC_REG_InitStruct.ContinuousMode = LL_ADC_REG_CONV_CONTINUOUS;
  ADC_REG_InitStruct.DMATransfer = LL_ADC_REG_DMA_TRANSFER_UNLIMITED;
  ADC_REG_InitStruct.Overrun = LL_ADC_REG_OVR_DATA_PRESERVED;
  LL_ADC_REG_Init(ADC4, &ADC_REG_InitStruct);
  LL_ADC_SetGainCompensation(ADC4, 0);
  LL_ADC_SetOverSamplingScope(ADC4, LL_ADC_OVS_DISABLE);

  /* Disable ADC deep power down (enabled by default after reset state) */
  LL_ADC_DisableDeepPowerDown(ADC4);
  /* Enable ADC internal voltage regulator */
  LL_ADC_EnableInternalRegulator(ADC4);
  /* Delay for ADC internal voltage regulator stabilization. */
  /* Compute number of CPU cycles to wait for, from delay in us. */
  /* Note: Variable divided by 2 to compensate partially */
  /* CPU processing cycles (depends on compilation optimization). */
  /* Note: If system core clock frequency is below 200kHz, wait time */
  /* is only a few CPU processing cycles. */
  uint32_t wait_loop_index;
  wait_loop_index = ((LL_ADC_DELAY_INTERNAL_REGUL_STAB_US * (SystemCoreClock / (100000 * 2))) / 10);
  while(wait_loop_index != 0)
  {
    wait_loop_index--;
  }

  /** Configure Regular Channel
  */

  /* USER CODE BEGIN ADC4_Init 2 */
	// 5-9
  LL_ADC_REG_SetSequencerRanks(ADC4, LL_ADC_REG_RANK_1, LL_ADC_CHANNEL_13);
  LL_ADC_SetChannelSamplingTime(ADC4, LL_ADC_CHANNEL_13, ADC_SAMPLE_TIME);
  LL_ADC_SetChannelSingleDiff(ADC4, LL_ADC_CHANNEL_13, LL_ADC_SINGLE_ENDED);

  LL_ADC_REG_SetSequencerRanks(ADC4, LL_ADC_REG_RANK_2, LL_ADC_CHANNEL_12);
  LL_ADC_SetChannelSamplingTime(ADC4, LL_ADC_CHANNEL_12, ADC_SAMPLE_TIME);
  LL_ADC_SetChannelSingleDiff(ADC4, LL_ADC_CHANNEL_12, LL_ADC_SINGLE_ENDED);

  LL_ADC_REG_SetSequencerRanks(ADC4, LL_ADC_REG_RANK_3, LL_ADC_CHANNEL_5);
  LL_ADC_SetChannelSamplingTime(ADC4, LL_ADC_CHANNEL_5, ADC_SAMPLE_TIME);
  LL_ADC_SetChannelSingleDiff(ADC4, LL_ADC_CHANNEL_5, LL_ADC_SINGLE_ENDED);

  LL_ADC_REG_SetSequencerRanks(ADC4, LL_ADC_REG_RANK_4, LL_ADC_CHANNEL_4);
  LL_ADC_SetChannelSamplingTime(ADC4, LL_ADC_CHANNEL_4, ADC_SAMPLE_TIME);
  LL_ADC_SetChannelSingleDiff(ADC4, LL_ADC_CHANNEL_4, LL_ADC_SINGLE_ENDED);

  LL_ADC_REG_SetSequencerRanks(ADC4, LL_ADC_REG_RANK_5, LL_ADC_CHANNEL_3);
  LL_ADC_SetChannelSamplingTime(ADC4, LL_ADC_CHANNEL_3, ADC_SAMPLE_TIME);
  LL_ADC_SetChannelSingleDiff(ADC4, LL_ADC_CHANNEL_3, LL_ADC_SINGLE_ENDED);

	//LL_ADC_REG_SetSequencerLength(ADC4,LL_ADC_REG_SEQ_SCAN_ENABLE_5RANKS);

  /* USER CODE END ADC4_Init 2 */

}

static void MX_ADC5_Init(void)
{

  LL_ADC_InitTypeDef ADC_InitStruct = {0};
  LL_ADC_REG_InitTypeDef ADC_REG_InitStruct = {0};
  LL_ADC_CommonInitTypeDef ADC_CommonInitStruct = {0};

  LL_GPIO_InitTypeDef GPIO_InitStruct = {0};

  LL_RCC_SetADCClockSource(LL_RCC_ADC345_CLKSOURCE_SYSCLK);

  /* Peripheral clock enable */
  LL_AHB2_GRP1_EnableClock(LL_AHB2_GRP1_PERIPH_ADC345);

  LL_AHB2_GRP1_EnableClock(LL_AHB2_GRP1_PERIPH_GPIOD);
  /**ADC5 GPIO Configuration
  PD10   ------> ADC5_IN7
  PD11   ------> ADC5_IN8
  PD12   ------> ADC5_IN9
  PD13   ------> ADC5_IN10
  PD14   ------> ADC5_IN11
  */
  GPIO_InitStruct.Pin = LL_GPIO_PIN_10;
  GPIO_InitStruct.Mode = LL_GPIO_MODE_ANALOG;
  GPIO_InitStruct.Pull = LL_GPIO_PULL_NO;
  LL_GPIO_Init(GPIOD, &GPIO_InitStruct);

  GPIO_InitStruct.Pin = LL_GPIO_PIN_11;
  GPIO_InitStruct.Mode = LL_GPIO_MODE_ANALOG;
  GPIO_InitStruct.Pull = LL_GPIO_PULL_NO;
  LL_GPIO_Init(GPIOD, &GPIO_InitStruct);

  GPIO_InitStruct.Pin = LL_GPIO_PIN_12;
  GPIO_InitStruct.Mode = LL_GPIO_MODE_ANALOG;
  GPIO_InitStruct.Pull = LL_GPIO_PULL_NO;
  LL_GPIO_Init(GPIOD, &GPIO_InitStruct);

  GPIO_InitStruct.Pin = LL_GPIO_PIN_13;
  GPIO_InitStruct.Mode = LL_GPIO_MODE_ANALOG;
  GPIO_InitStruct.Pull = LL_GPIO_PULL_NO;
  LL_GPIO_Init(GPIOD, &GPIO_InitStruct);

  GPIO_InitStruct.Pin = LL_GPIO_PIN_14;
  GPIO_InitStruct.Mode = LL_GPIO_MODE_ANALOG;
  GPIO_InitStruct.Pull = LL_GPIO_PULL_NO;
  LL_GPIO_Init(GPIOD, &GPIO_InitStruct);

  /* ADC5 DMA Init */

  /* ADC5 Init */
  LL_DMA_SetPeriphRequest(DMA1, LL_DMA_CHANNEL_5, LL_DMAMUX_REQ_ADC5);

  LL_DMA_SetDataTransferDirection(DMA1, LL_DMA_CHANNEL_5, LL_DMA_DIRECTION_PERIPH_TO_MEMORY);

  LL_DMA_SetChannelPriorityLevel(DMA1, LL_DMA_CHANNEL_5, LL_DMA_PRIORITY_LOW);

  LL_DMA_SetMode(DMA1, LL_DMA_CHANNEL_5, LL_DMA_MODE_NORMAL);

  LL_DMA_SetPeriphIncMode(DMA1, LL_DMA_CHANNEL_5, LL_DMA_PERIPH_NOINCREMENT);

  LL_DMA_SetMemoryIncMode(DMA1, LL_DMA_CHANNEL_5, LL_DMA_MEMORY_INCREMENT);

  LL_DMA_SetPeriphSize(DMA1, LL_DMA_CHANNEL_5, LL_DMA_PDATAALIGN_HALFWORD);

  LL_DMA_SetMemorySize(DMA1, LL_DMA_CHANNEL_5, LL_DMA_MDATAALIGN_HALFWORD);

  /** Common config
  */
  ADC_InitStruct.Resolution = LL_ADC_RESOLUTION_12B;
  ADC_InitStruct.DataAlignment = LL_ADC_DATA_ALIGN_RIGHT;
  ADC_InitStruct.LowPowerMode = LL_ADC_LP_MODE_NONE;
  LL_ADC_Init(ADC5, &ADC_InitStruct);
  ADC_REG_InitStruct.TriggerSource = LL_ADC_REG_TRIG_SOFTWARE;
  ADC_REG_InitStruct.SequencerLength = LL_ADC_REG_SEQ_SCAN_ENABLE_5RANKS;
  ADC_REG_InitStruct.SequencerDiscont = LL_ADC_REG_SEQ_DISCONT_DISABLE;
  ADC_REG_InitStruct.ContinuousMode = LL_ADC_REG_CONV_CONTINUOUS;
  ADC_REG_InitStruct.DMATransfer = LL_ADC_REG_DMA_TRANSFER_UNLIMITED;
  ADC_REG_InitStruct.Overrun = LL_ADC_REG_OVR_DATA_PRESERVED;
  LL_ADC_REG_Init(ADC5, &ADC_REG_InitStruct);
  LL_ADC_SetGainCompensation(ADC5, 0);
  LL_ADC_SetOverSamplingScope(ADC5, LL_ADC_OVS_DISABLE);
  ADC_CommonInitStruct.CommonClock = LL_ADC_CLOCK_ASYNC_DIV16;
  LL_ADC_CommonInit(__LL_ADC_COMMON_INSTANCE(ADC5), &ADC_CommonInitStruct);

  /* Disable ADC deep power down (enabled by default after reset state) */
  LL_ADC_DisableDeepPowerDown(ADC5);
  /* Enable ADC internal voltage regulator */
  LL_ADC_EnableInternalRegulator(ADC5);
  /* Delay for ADC internal voltage regulator stabilization. */
  /* Compute number of CPU cycles to wait for, from delay in us. */
  /* Note: Variable divided by 2 to compensate partially */
  /* CPU processing cycles (depends on compilation optimization). */
  /* Note: If system core clock frequency is below 200kHz, wait time */
  /* is only a few CPU processing cycles. */
  uint32_t wait_loop_index;
  wait_loop_index = ((LL_ADC_DELAY_INTERNAL_REGUL_STAB_US * (SystemCoreClock / (100000 * 2))) / 10);
  while(wait_loop_index != 0)
  {
    wait_loop_index--;
  }

  /** Configure Regular Channel
  */

  /* USER CODE BEGIN ADC5_Init 2 */

  LL_ADC_REG_SetSequencerRanks(ADC5, LL_ADC_REG_RANK_1, LL_ADC_CHANNEL_10);
  LL_ADC_SetChannelSamplingTime(ADC5, LL_ADC_CHANNEL_10, ADC_SAMPLE_TIME);
  LL_ADC_SetChannelSingleDiff(ADC5, LL_ADC_CHANNEL_10, LL_ADC_SINGLE_ENDED);

  LL_ADC_REG_SetSequencerRanks(ADC5, LL_ADC_REG_RANK_2, LL_ADC_CHANNEL_9);
  LL_ADC_SetChannelSamplingTime(ADC5, LL_ADC_CHANNEL_9, ADC_SAMPLE_TIME);
  LL_ADC_SetChannelSingleDiff(ADC5, LL_ADC_CHANNEL_9, LL_ADC_SINGLE_ENDED);

  LL_ADC_REG_SetSequencerRanks(ADC5, LL_ADC_REG_RANK_3, LL_ADC_CHANNEL_8);
  LL_ADC_SetChannelSamplingTime(ADC5, LL_ADC_CHANNEL_8, ADC_SAMPLE_TIME);
  LL_ADC_SetChannelSingleDiff(ADC5, LL_ADC_CHANNEL_8, LL_ADC_SINGLE_ENDED);

  LL_ADC_REG_SetSequencerRanks(ADC5, LL_ADC_REG_RANK_4, LL_ADC_CHANNEL_7);
  LL_ADC_SetChannelSamplingTime(ADC5, LL_ADC_CHANNEL_7, ADC_SAMPLE_TIME);
  LL_ADC_SetChannelSingleDiff(ADC5, LL_ADC_CHANNEL_7, LL_ADC_SINGLE_ENDED);

	LL_ADC_REG_SetSequencerRanks(ADC5, LL_ADC_REG_RANK_5, LL_ADC_CHANNEL_11);
  LL_ADC_SetChannelSamplingTime(ADC5, LL_ADC_CHANNEL_11, ADC_SAMPLE_TIME);
  LL_ADC_SetChannelSingleDiff(ADC5, LL_ADC_CHANNEL_11, LL_ADC_SINGLE_ENDED);

	//LL_ADC_REG_SetSequencerLength(ADC5,LL_ADC_REG_SEQ_SCAN_ENABLE_5RANKS);

  /* USER CODE END ADC5_Init 2 */

}

static void MX_DAC1_Init(void)
{

  LL_DAC_InitTypeDef DAC_InitStruct = {0};

  LL_GPIO_InitTypeDef GPIO_InitStruct = {0};

  /* Peripheral clock enable */
  LL_AHB2_GRP1_EnableClock(LL_AHB2_GRP1_PERIPH_DAC1);

  LL_AHB2_GRP1_EnableClock(LL_AHB2_GRP1_PERIPH_GPIOA);
  /**DAC1 GPIO Configuration
  PA4   ------> DAC1_OUT1
  */
  GPIO_InitStruct.Pin = LL_GPIO_PIN_4;
  GPIO_InitStruct.Mode = LL_GPIO_MODE_ANALOG;
  GPIO_InitStruct.Pull = LL_GPIO_PULL_NO;
  LL_GPIO_Init(GPIOA, &GPIO_InitStruct);

  /** DAC channel OUT1 config
  */
  LL_DAC_SetSignedFormat(DAC1, LL_DAC_CHANNEL_1, LL_DAC_SIGNED_FORMAT_DISABLE);
  DAC_InitStruct.TriggerSource = LL_DAC_TRIG_SOFTWARE;
  DAC_InitStruct.TriggerSource2 = LL_DAC_TRIG_SOFTWARE;
  DAC_InitStruct.WaveAutoGeneration = LL_DAC_WAVE_AUTO_GENERATION_NONE;
  DAC_InitStruct.OutputBuffer = LL_DAC_OUTPUT_BUFFER_ENABLE;
  DAC_InitStruct.OutputConnection = LL_DAC_OUTPUT_CONNECT_GPIO;
  DAC_InitStruct.OutputMode = LL_DAC_OUTPUT_MODE_NORMAL;
  LL_DAC_Init(DAC1, LL_DAC_CHANNEL_1, &DAC_InitStruct);
  LL_DAC_DisableTrigger(DAC1, LL_DAC_CHANNEL_1);
  LL_DAC_DisableDMADoubleDataMode(DAC1, LL_DAC_CHANNEL_1);

}

static void MX_DAC2_Init(void)
{

  LL_DAC_InitTypeDef DAC_InitStruct = {0};

  LL_GPIO_InitTypeDef GPIO_InitStruct = {0};

  /* Peripheral clock enable */
  LL_AHB2_GRP1_EnableClock(LL_AHB2_GRP1_PERIPH_DAC2);

  LL_AHB2_GRP1_EnableClock(LL_AHB2_GRP1_PERIPH_GPIOA);
  /**DAC2 GPIO Configuration
  PA6   ------> DAC2_OUT1
  */
  GPIO_InitStruct.Pin = LL_GPIO_PIN_6;
  GPIO_InitStruct.Mode = LL_GPIO_MODE_ANALOG;
  GPIO_InitStruct.Pull = LL_GPIO_PULL_NO;
  LL_GPIO_Init(GPIOA, &GPIO_InitStruct);

  /** DAC channel OUT1 config
  */
  LL_DAC_SetSignedFormat(DAC2, LL_DAC_CHANNEL_1, LL_DAC_SIGNED_FORMAT_DISABLE);
  DAC_InitStruct.TriggerSource = LL_DAC_TRIG_SOFTWARE;
  DAC_InitStruct.TriggerSource2 = LL_DAC_TRIG_SOFTWARE;
  DAC_InitStruct.WaveAutoGeneration = LL_DAC_WAVE_AUTO_GENERATION_NONE;
  DAC_InitStruct.OutputBuffer = LL_DAC_OUTPUT_BUFFER_ENABLE;
  DAC_InitStruct.OutputConnection = LL_DAC_OUTPUT_CONNECT_GPIO;
  DAC_InitStruct.OutputMode = LL_DAC_OUTPUT_MODE_NORMAL;
  LL_DAC_Init(DAC2, LL_DAC_CHANNEL_1, &DAC_InitStruct);
  LL_DAC_DisableTrigger(DAC2, LL_DAC_CHANNEL_1);
  LL_DAC_DisableDMADoubleDataMode(DAC2, LL_DAC_CHANNEL_1);

}

static void MX_IWDG_Init(void)
{

  LL_IWDG_Enable(IWDG);
  LL_IWDG_EnableWriteAccess(IWDG);
  LL_IWDG_SetPrescaler(IWDG, LL_IWDG_PRESCALER_64);
  LL_IWDG_SetReloadCounter(IWDG, 4095);
  while (LL_IWDG_IsReady(IWDG) != 1)
  {
  }

  LL_IWDG_ReloadCounter(IWDG);

}

static void MX_TIM1_Init(void)
{

  LL_TIM_InitTypeDef TIM_InitStruct = {0};

  /* Peripheral clock enable */
  LL_APB2_GRP1_EnableClock(LL_APB2_GRP1_PERIPH_TIM1);

  TIM_InitStruct.Prescaler = 1680-1;
  TIM_InitStruct.CounterMode = LL_TIM_COUNTERMODE_UP;
  TIM_InitStruct.Autoreload = 65535;
  TIM_InitStruct.ClockDivision = LL_TIM_CLOCKDIVISION_DIV1;
  TIM_InitStruct.RepetitionCounter = 0;
  LL_TIM_Init(TIM1, &TIM_InitStruct);
  LL_TIM_DisableARRPreload(TIM1);
  LL_TIM_SetClockSource(TIM1, LL_TIM_CLOCKSOURCE_INTERNAL);
  LL_TIM_SetTriggerOutput(TIM1, LL_TIM_TRGO_RESET);
  LL_TIM_SetTriggerOutput2(TIM1, LL_TIM_TRGO2_RESET);
  LL_TIM_DisableMasterSlaveMode(TIM1);

}

static void MX_TIM2_Init(void)
{

  LL_TIM_InitTypeDef TIM_InitStruct = {0};

  /* Peripheral clock enable */
  LL_APB1_GRP1_EnableClock(LL_APB1_GRP1_PERIPH_TIM2);

  TIM_InitStruct.Prescaler = 0;
  TIM_InitStruct.CounterMode = LL_TIM_COUNTERMODE_UP;
  TIM_InitStruct.Autoreload = 4294967295;
  TIM_InitStruct.ClockDivision = LL_TIM_CLOCKDIVISION_DIV1;
  LL_TIM_Init(TIM2, &TIM_InitStruct);
  LL_TIM_DisableARRPreload(TIM2);
  LL_TIM_SetClockSource(TIM2, LL_TIM_CLOCKSOURCE_INTERNAL);
  LL_TIM_SetTriggerOutput(TIM2, LL_TIM_TRGO_RESET);
  LL_TIM_DisableMasterSlaveMode(TIM2);

}

static void MX_TIM3_Init(void)
{

  LL_TIM_InitTypeDef TIM_InitStruct = {0};

  /* Peripheral clock enable */
  LL_APB1_GRP1_EnableClock(LL_APB1_GRP1_PERIPH_TIM3);

  TIM_InitStruct.Prescaler = 0;
  TIM_InitStruct.CounterMode = LL_TIM_COUNTERMODE_UP;
  TIM_InitStruct.Autoreload = 65535;
  TIM_InitStruct.ClockDivision = LL_TIM_CLOCKDIVISION_DIV1;
  LL_TIM_Init(TIM3, &TIM_InitStruct);
  LL_TIM_DisableARRPreload(TIM3);
  LL_TIM_SetClockSource(TIM3, LL_TIM_CLOCKSOURCE_INTERNAL);
  LL_TIM_SetTriggerOutput(TIM3, LL_TIM_TRGO_RESET);
  LL_TIM_DisableMasterSlaveMode(TIM3);

}

static void MX_UART4_Init(void)
{

  LL_USART_InitTypeDef USART_InitStruct = {0};

  LL_GPIO_InitTypeDef GPIO_InitStruct = {0};

  LL_RCC_SetUARTClockSource(LL_RCC_UART4_CLKSOURCE_PCLK1);

  /* Peripheral clock enable */
  LL_APB1_GRP1_EnableClock(LL_APB1_GRP1_PERIPH_UART4);

  LL_AHB2_GRP1_EnableClock(LL_AHB2_GRP1_PERIPH_GPIOC);
  /**UART4 GPIO Configuration
  PC10   ------> UART4_TX
  PC11   ------> UART4_RX
  */
  GPIO_InitStruct.Pin = LL_GPIO_PIN_10;
  GPIO_InitStruct.Mode = LL_GPIO_MODE_ALTERNATE;
  GPIO_InitStruct.Speed = LL_GPIO_SPEED_FREQ_LOW;
  GPIO_InitStruct.OutputType = LL_GPIO_OUTPUT_PUSHPULL;
  GPIO_InitStruct.Pull = LL_GPIO_PULL_NO;
  GPIO_InitStruct.Alternate = LL_GPIO_AF_5;
  LL_GPIO_Init(GPIOC, &GPIO_InitStruct);

  GPIO_InitStruct.Pin = LL_GPIO_PIN_11;
  GPIO_InitStruct.Mode = LL_GPIO_MODE_ALTERNATE;
  GPIO_InitStruct.Speed = LL_GPIO_SPEED_FREQ_LOW;
  GPIO_InitStruct.OutputType = LL_GPIO_OUTPUT_PUSHPULL;
  GPIO_InitStruct.Pull = LL_GPIO_PULL_NO;
  GPIO_InitStruct.Alternate = LL_GPIO_AF_5;
  LL_GPIO_Init(GPIOC, &GPIO_InitStruct);

  /* UART4 interrupt Init */
  NVIC_SetPriority(UART4_IRQn, NVIC_EncodePriority(NVIC_GetPriorityGrouping(),2, 0));
  NVIC_EnableIRQ(UART4_IRQn);

  USART_InitStruct.PrescalerValue = LL_USART_PRESCALER_DIV1;
  USART_InitStruct.BaudRate = 115200;
  USART_InitStruct.DataWidth = LL_USART_DATAWIDTH_8B;
  USART_InitStruct.StopBits = LL_USART_STOPBITS_1;
  USART_InitStruct.Parity = LL_USART_PARITY_NONE;
  USART_InitStruct.TransferDirection = LL_USART_DIRECTION_TX_RX;
  USART_InitStruct.HardwareFlowControl = LL_USART_HWCONTROL_NONE;
  USART_InitStruct.OverSampling = LL_USART_OVERSAMPLING_16;
  LL_USART_Init(UART4, &USART_InitStruct);
  LL_USART_DisableFIFO(UART4);
  LL_USART_SetTXFIFOThreshold(UART4, LL_USART_FIFOTHRESHOLD_1_2);
  LL_USART_SetRXFIFOThreshold(UART4, LL_USART_FIFOTHRESHOLD_1_2);
  LL_USART_ConfigAsyncMode(UART4);

  /* USER CODE BEGIN WKUPType UART4 */
	LL_USART_EnableIT_RXNE(UART4);
	LL_USART_EnableIT_IDLE(UART4);
  /* USER CODE END WKUPType UART4 */

  LL_USART_Enable(UART4);

  /* Polling UART4 initialisation */
  while((!(LL_USART_IsActiveFlag_TEACK(UART4))) || (!(LL_USART_IsActiveFlag_REACK(UART4))))
  {
  }

}

static void MX_UART5_Init(void)
{

  LL_USART_InitTypeDef USART_InitStruct = {0};

  LL_GPIO_InitTypeDef GPIO_InitStruct = {0};

  LL_RCC_SetUARTClockSource(LL_RCC_UART5_CLKSOURCE_PCLK1);

  /* Peripheral clock enable */
  LL_APB1_GRP1_EnableClock(LL_APB1_GRP1_PERIPH_UART5);

  LL_AHB2_GRP1_EnableClock(LL_AHB2_GRP1_PERIPH_GPIOC);
  LL_AHB2_GRP1_EnableClock(LL_AHB2_GRP1_PERIPH_GPIOD);
  /**UART5 GPIO Configuration
  PC12   ------> UART5_TX
  PD2   ------> UART5_RX
  */
  GPIO_InitStruct.Pin = LL_GPIO_PIN_12;
  GPIO_InitStruct.Mode = LL_GPIO_MODE_ALTERNATE;
  GPIO_InitStruct.Speed = LL_GPIO_SPEED_FREQ_LOW;
  GPIO_InitStruct.OutputType = LL_GPIO_OUTPUT_PUSHPULL;
  GPIO_InitStruct.Pull = LL_GPIO_PULL_NO;
  GPIO_InitStruct.Alternate = LL_GPIO_AF_5;
  LL_GPIO_Init(GPIOC, &GPIO_InitStruct);

  GPIO_InitStruct.Pin = LL_GPIO_PIN_2;
  GPIO_InitStruct.Mode = LL_GPIO_MODE_ALTERNATE;
  GPIO_InitStruct.Speed = LL_GPIO_SPEED_FREQ_LOW;
  GPIO_InitStruct.OutputType = LL_GPIO_OUTPUT_PUSHPULL;
  GPIO_InitStruct.Pull = LL_GPIO_PULL_NO;
  GPIO_InitStruct.Alternate = LL_GPIO_AF_5;
  LL_GPIO_Init(GPIOD, &GPIO_InitStruct);

  /* UART5 interrupt Init */
  NVIC_SetPriority(UART5_IRQn, NVIC_EncodePriority(NVIC_GetPriorityGrouping(),2, 0));
  NVIC_EnableIRQ(UART5_IRQn);

  USART_InitStruct.PrescalerValue = LL_USART_PRESCALER_DIV1;
  USART_InitStruct.BaudRate = 115200;
  USART_InitStruct.DataWidth = LL_USART_DATAWIDTH_8B;
  USART_InitStruct.StopBits = LL_USART_STOPBITS_1;
  USART_InitStruct.Parity = LL_USART_PARITY_NONE;
  USART_InitStruct.TransferDirection = LL_USART_DIRECTION_TX_RX;
  USART_InitStruct.HardwareFlowControl = LL_USART_HWCONTROL_NONE;
  USART_InitStruct.OverSampling = LL_USART_OVERSAMPLING_16;
  LL_USART_Init(UART5, &USART_InitStruct);
  LL_USART_DisableFIFO(UART5);
  LL_USART_SetTXFIFOThreshold(UART5, LL_USART_FIFOTHRESHOLD_1_2);
  LL_USART_SetRXFIFOThreshold(UART5, LL_USART_FIFOTHRESHOLD_1_2);
  LL_USART_ConfigAsyncMode(UART5);

  /* USER CODE BEGIN WKUPType UART5 */
	LL_USART_EnableIT_RXNE(UART5);
	LL_USART_EnableIT_IDLE(UART5);

  /* USER CODE END WKUPType UART5 */

  LL_USART_Enable(UART5);

  /* Polling UART5 initialisation */
  while((!(LL_USART_IsActiveFlag_TEACK(UART5))) || (!(LL_USART_IsActiveFlag_REACK(UART5))))
  {
  }

}

static void MX_USART1_UART_Init(void)
{

  LL_USART_InitTypeDef USART_InitStruct = {0};

  LL_GPIO_InitTypeDef GPIO_InitStruct = {0};

  LL_RCC_SetUSARTClockSource(LL_RCC_USART1_CLKSOURCE_PCLK2);

  /* Peripheral clock enable */
  LL_APB2_GRP1_EnableClock(LL_APB2_GRP1_PERIPH_USART1);

  LL_AHB2_GRP1_EnableClock(LL_AHB2_GRP1_PERIPH_GPIOE);
  /**USART1 GPIO Configuration
  PE0   ------> USART1_TX
  PE1   ------> USART1_RX
  */
  GPIO_InitStruct.Pin = LL_GPIO_PIN_0;
  GPIO_InitStruct.Mode = LL_GPIO_MODE_ALTERNATE;
  GPIO_InitStruct.Speed = LL_GPIO_SPEED_FREQ_LOW;
  GPIO_InitStruct.OutputType = LL_GPIO_OUTPUT_PUSHPULL;
  GPIO_InitStruct.Pull = LL_GPIO_PULL_NO;
  GPIO_InitStruct.Alternate = LL_GPIO_AF_7;
  LL_GPIO_Init(GPIOE, &GPIO_InitStruct);

  GPIO_InitStruct.Pin = LL_GPIO_PIN_1;
  GPIO_InitStruct.Mode = LL_GPIO_MODE_ALTERNATE;
  GPIO_InitStruct.Speed = LL_GPIO_SPEED_FREQ_LOW;
  GPIO_InitStruct.OutputType = LL_GPIO_OUTPUT_PUSHPULL;
  GPIO_InitStruct.Pull = LL_GPIO_PULL_NO;
  GPIO_InitStruct.Alternate = LL_GPIO_AF_7;
  LL_GPIO_Init(GPIOE, &GPIO_InitStruct);

  USART_InitStruct.PrescalerValue = LL_USART_PRESCALER_DIV1;
  USART_InitStruct.BaudRate = 115200;
  USART_InitStruct.DataWidth = LL_USART_DATAWIDTH_8B;
  USART_InitStruct.StopBits = LL_USART_STOPBITS_1;
  USART_InitStruct.Parity = LL_USART_PARITY_NONE;
  USART_InitStruct.TransferDirection = LL_USART_DIRECTION_TX_RX;
  USART_InitStruct.HardwareFlowControl = LL_USART_HWCONTROL_NONE;
  USART_InitStruct.OverSampling = LL_USART_OVERSAMPLING_16;
  LL_USART_Init(USART1, &USART_InitStruct);

  LL_USART_SetTXFIFOThreshold(USART1, LL_USART_FIFOTHRESHOLD_1_2);
  LL_USART_SetRXFIFOThreshold(USART1, LL_USART_FIFOTHRESHOLD_1_2);
  LL_USART_DisableFIFO(USART1);

  LL_USART_ConfigAsyncMode(USART1);

  /* USER CODE BEGIN WKUPType USART1 */
	LL_USART_EnableIT_RXNE(USART1);
	LL_USART_EnableIT_IDLE(USART1);
  /* USER CODE END WKUPType USART1 */

  LL_USART_Enable(USART1);

  /* Polling USART1 initialisation */
  while((!(LL_USART_IsActiveFlag_TEACK(USART1))) || (!(LL_USART_IsActiveFlag_REACK(USART1))))
  {
  }
  /* USER CODE BEGIN USART1_Init 2 */
	NVIC_SetPriority(USART1_IRQn, NVIC_EncodePriority(NVIC_GetPriorityGrouping(),3, 3));
  NVIC_EnableIRQ(USART1_IRQn);

  /* USER CODE END USART1_Init 2 */

}

static void MX_DMA_Init(void)
{

  /* Init with LL driver */
  /* DMA controller clock enable */
  LL_AHB1_GRP1_EnableClock(LL_AHB1_GRP1_PERIPH_DMAMUX1);
  LL_AHB1_GRP1_EnableClock(LL_AHB1_GRP1_PERIPH_DMA1);

  /* DMA interrupt init */
  /* DMA1_Channel1_IRQn interrupt configuration */
	#if 0
  NVIC_SetPriority(DMA1_Channel1_IRQn, NVIC_EncodePriority(NVIC_GetPriorityGrouping(),0, 0));
  NVIC_EnableIRQ(DMA1_Channel1_IRQn);
  /* DMA1_Channel2_IRQn interrupt configuration */
  NVIC_SetPriority(DMA1_Channel2_IRQn, NVIC_EncodePriority(NVIC_GetPriorityGrouping(),0, 0));
  NVIC_EnableIRQ(DMA1_Channel2_IRQn);
  /* DMA1_Channel3_IRQn interrupt configuration */
  NVIC_SetPriority(DMA1_Channel3_IRQn, NVIC_EncodePriority(NVIC_GetPriorityGrouping(),0, 0));
  NVIC_EnableIRQ(DMA1_Channel3_IRQn);
  /* DMA1_Channel4_IRQn interrupt configuration */
  NVIC_SetPriority(DMA1_Channel4_IRQn, NVIC_EncodePriority(NVIC_GetPriorityGrouping(),0, 0));
  NVIC_EnableIRQ(DMA1_Channel4_IRQn);
  /* DMA1_Channel5_IRQn interrupt configuration */
  NVIC_SetPriority(DMA1_Channel5_IRQn, NVIC_EncodePriority(NVIC_GetPriorityGrouping(),0, 0));
  NVIC_EnableIRQ(DMA1_Channel5_IRQn);
	#endif
}

static void MX_GPIO_Init(void)
{
  LL_GPIO_InitTypeDef GPIO_InitStruct = {0};

  /* GPIO Ports Clock Enable */
  LL_AHB2_GRP1_EnableClock(LL_AHB2_GRP1_PERIPH_GPIOE);
  LL_AHB2_GRP1_EnableClock(LL_AHB2_GRP1_PERIPH_GPIOC);
  LL_AHB2_GRP1_EnableClock(LL_AHB2_GRP1_PERIPH_GPIOF);
  LL_AHB2_GRP1_EnableClock(LL_AHB2_GRP1_PERIPH_GPIOA);
  LL_AHB2_GRP1_EnableClock(LL_AHB2_GRP1_PERIPH_GPIOB);
  LL_AHB2_GRP1_EnableClock(LL_AHB2_GRP1_PERIPH_GPIOD);
  LL_AHB2_GRP1_EnableClock(LL_AHB2_GRP1_PERIPH_GPIOG);

  /**/
  LL_GPIO_ResetOutputPin(LED_GPIO_Port, LED_Pin);

  /**/
  LL_GPIO_ResetOutputPin(EN1_GPIO_Port, EN1_Pin);

  /**/
  LL_GPIO_ResetOutputPin(EN2_GPIO_Port, EN2_Pin);

  /**/
  LL_GPIO_ResetOutputPin(EN3_GPIO_Port, EN3_Pin);

  /**/
  LL_GPIO_ResetOutputPin(EN4_GPIO_Port, EN4_Pin);

  /**/
  LL_GPIO_ResetOutputPin(EN5_GPIO_Port, EN5_Pin);

  /**/
  LL_GPIO_ResetOutputPin(EN6_GPIO_Port, EN6_Pin);

  /**/
  LL_GPIO_ResetOutputPin(EN7_GPIO_Port, EN7_Pin);

  /**/
  LL_GPIO_ResetOutputPin(EN8_GPIO_Port, EN8_Pin);

  /**/
  LL_GPIO_ResetOutputPin(EN9_GPIO_Port, EN9_Pin);

  /**/
  LL_GPIO_ResetOutputPin(EN10_GPIO_Port, EN10_Pin);

  /**/
  LL_GPIO_ResetOutputPin(EN11_GPIO_Port, EN11_Pin);

  /**/
  LL_GPIO_ResetOutputPin(EN12_GPIO_Port, EN12_Pin);

  /**/
  LL_GPIO_ResetOutputPin(EN13_GPIO_Port, EN13_Pin);

  /**/
  LL_GPIO_ResetOutputPin(EN14_GPIO_Port, EN14_Pin);

  /**/
  LL_GPIO_ResetOutputPin(EN15_GPIO_Port, EN15_Pin);

  /**/
  LL_GPIO_ResetOutputPin(EN16_GPIO_Port, EN16_Pin);

  /**/
  LL_GPIO_ResetOutputPin(EN17_GPIO_Port, EN17_Pin);

  /**/
  LL_GPIO_ResetOutputPin(EN18_GPIO_Port, EN18_Pin);

  /**/
  LL_GPIO_ResetOutputPin(EN19_GPIO_Port, EN19_Pin);

  /**/
  LL_GPIO_ResetOutputPin(EN20_GPIO_Port, EN20_Pin);

  /**/
  LL_GPIO_ResetOutputPin(EN21_GPIO_Port, EN21_Pin);

  /**/
  LL_GPIO_ResetOutputPin(EN22_GPIO_Port, EN22_Pin);

  /**/
  LL_GPIO_ResetOutputPin(EN23_GPIO_Port, EN23_Pin);

  /**/
  LL_GPIO_ResetOutputPin(EN24_GPIO_Port, EN24_Pin);

  /**/
  LL_GPIO_ResetOutputPin(D_CLR_GPIO_Port, D_CLR_Pin);

  /**/
  LL_GPIO_ResetOutputPin(EN_1_2V_GPIO_Port, EN_1_2V_Pin);

  /**/
  GPIO_InitStruct.Pin = AR1_Pin;
  GPIO_InitStruct.Mode = LL_GPIO_MODE_INPUT;
  GPIO_InitStruct.Pull = LL_GPIO_PULL_UP;
  LL_GPIO_Init(AR1_GPIO_Port, &GPIO_InitStruct);

  /**/
  GPIO_InitStruct.Pin = AR2_Pin;
  GPIO_InitStruct.Mode = LL_GPIO_MODE_INPUT;
  GPIO_InitStruct.Pull = LL_GPIO_PULL_UP;
  LL_GPIO_Init(AR2_GPIO_Port, &GPIO_InitStruct);

  /**/
  GPIO_InitStruct.Pin = AR3_Pin;
  GPIO_InitStruct.Mode = LL_GPIO_MODE_INPUT;
  GPIO_InitStruct.Pull = LL_GPIO_PULL_UP;
  LL_GPIO_Init(AR3_GPIO_Port, &GPIO_InitStruct);

  /**/
  GPIO_InitStruct.Pin = AR4_Pin;
  GPIO_InitStruct.Mode = LL_GPIO_MODE_INPUT;
  GPIO_InitStruct.Pull = LL_GPIO_PULL_UP;
  LL_GPIO_Init(AR4_GPIO_Port, &GPIO_InitStruct);

  /**/
  GPIO_InitStruct.Pin = LED_Pin;
  GPIO_InitStruct.Mode = LL_GPIO_MODE_OUTPUT;
  GPIO_InitStruct.Speed = LL_GPIO_SPEED_FREQ_LOW;
  GPIO_InitStruct.OutputType = LL_GPIO_OUTPUT_PUSHPULL;
  GPIO_InitStruct.Pull = LL_GPIO_PULL_NO;
  LL_GPIO_Init(LED_GPIO_Port, &GPIO_InitStruct);

  /**/
  GPIO_InitStruct.Pin = START_Pin;
  GPIO_InitStruct.Mode = LL_GPIO_MODE_INPUT;
  GPIO_InitStruct.Pull = LL_GPIO_PULL_UP;
  LL_GPIO_Init(START_GPIO_Port, &GPIO_InitStruct);

  /**/
  GPIO_InitStruct.Pin = STOP_Pin;
  GPIO_InitStruct.Mode = LL_GPIO_MODE_INPUT;
  GPIO_InitStruct.Pull = LL_GPIO_PULL_UP;
  LL_GPIO_Init(STOP_GPIO_Port, &GPIO_InitStruct);

  /**/
  GPIO_InitStruct.Pin = EN1_Pin;
  GPIO_InitStruct.Mode = LL_GPIO_MODE_OUTPUT;
  GPIO_InitStruct.Speed = LL_GPIO_SPEED_FREQ_LOW;
  GPIO_InitStruct.OutputType = LL_GPIO_OUTPUT_PUSHPULL;
  GPIO_InitStruct.Pull = LL_GPIO_PULL_NO;
  LL_GPIO_Init(EN1_GPIO_Port, &GPIO_InitStruct);

  /**/
  GPIO_InitStruct.Pin = EN2_Pin;
  GPIO_InitStruct.Mode = LL_GPIO_MODE_OUTPUT;
  GPIO_InitStruct.Speed = LL_GPIO_SPEED_FREQ_LOW;
  GPIO_InitStruct.OutputType = LL_GPIO_OUTPUT_PUSHPULL;
  GPIO_InitStruct.Pull = LL_GPIO_PULL_NO;
  LL_GPIO_Init(EN2_GPIO_Port, &GPIO_InitStruct);

  /**/
  GPIO_InitStruct.Pin = EN3_Pin;
  GPIO_InitStruct.Mode = LL_GPIO_MODE_OUTPUT;
  GPIO_InitStruct.Speed = LL_GPIO_SPEED_FREQ_LOW;
  GPIO_InitStruct.OutputType = LL_GPIO_OUTPUT_PUSHPULL;
  GPIO_InitStruct.Pull = LL_GPIO_PULL_NO;
  LL_GPIO_Init(EN3_GPIO_Port, &GPIO_InitStruct);

  /**/
  GPIO_InitStruct.Pin = EN4_Pin;
  GPIO_InitStruct.Mode = LL_GPIO_MODE_OUTPUT;
  GPIO_InitStruct.Speed = LL_GPIO_SPEED_FREQ_LOW;
  GPIO_InitStruct.OutputType = LL_GPIO_OUTPUT_PUSHPULL;
  GPIO_InitStruct.Pull = LL_GPIO_PULL_NO;
  LL_GPIO_Init(EN4_GPIO_Port, &GPIO_InitStruct);

  /**/
  GPIO_InitStruct.Pin = EN5_Pin;
  GPIO_InitStruct.Mode = LL_GPIO_MODE_OUTPUT;
  GPIO_InitStruct.Speed = LL_GPIO_SPEED_FREQ_LOW;
  GPIO_InitStruct.OutputType = LL_GPIO_OUTPUT_PUSHPULL;
  GPIO_InitStruct.Pull = LL_GPIO_PULL_NO;
  LL_GPIO_Init(EN5_GPIO_Port, &GPIO_InitStruct);

  /**/
  GPIO_InitStruct.Pin = EN6_Pin;
  GPIO_InitStruct.Mode = LL_GPIO_MODE_OUTPUT;
  GPIO_InitStruct.Speed = LL_GPIO_SPEED_FREQ_LOW;
  GPIO_InitStruct.OutputType = LL_GPIO_OUTPUT_PUSHPULL;
  GPIO_InitStruct.Pull = LL_GPIO_PULL_NO;
  LL_GPIO_Init(EN6_GPIO_Port, &GPIO_InitStruct);

  /**/
  GPIO_InitStruct.Pin = EN7_Pin;
  GPIO_InitStruct.Mode = LL_GPIO_MODE_OUTPUT;
  GPIO_InitStruct.Speed = LL_GPIO_SPEED_FREQ_LOW;
  GPIO_InitStruct.OutputType = LL_GPIO_OUTPUT_PUSHPULL;
  GPIO_InitStruct.Pull = LL_GPIO_PULL_NO;
  LL_GPIO_Init(EN7_GPIO_Port, &GPIO_InitStruct);

  /**/
  GPIO_InitStruct.Pin = EN8_Pin;
  GPIO_InitStruct.Mode = LL_GPIO_MODE_OUTPUT;
  GPIO_InitStruct.Speed = LL_GPIO_SPEED_FREQ_LOW;
  GPIO_InitStruct.OutputType = LL_GPIO_OUTPUT_PUSHPULL;
  GPIO_InitStruct.Pull = LL_GPIO_PULL_NO;
  LL_GPIO_Init(EN8_GPIO_Port, &GPIO_InitStruct);

  /**/
  GPIO_InitStruct.Pin = EN9_Pin;
  GPIO_InitStruct.Mode = LL_GPIO_MODE_OUTPUT;
  GPIO_InitStruct.Speed = LL_GPIO_SPEED_FREQ_LOW;
  GPIO_InitStruct.OutputType = LL_GPIO_OUTPUT_PUSHPULL;
  GPIO_InitStruct.Pull = LL_GPIO_PULL_NO;
  LL_GPIO_Init(EN9_GPIO_Port, &GPIO_InitStruct);

  /**/
  GPIO_InitStruct.Pin = EN10_Pin;
  GPIO_InitStruct.Mode = LL_GPIO_MODE_OUTPUT;
  GPIO_InitStruct.Speed = LL_GPIO_SPEED_FREQ_LOW;
  GPIO_InitStruct.OutputType = LL_GPIO_OUTPUT_PUSHPULL;
  GPIO_InitStruct.Pull = LL_GPIO_PULL_NO;
  LL_GPIO_Init(EN10_GPIO_Port, &GPIO_InitStruct);

  /**/
  GPIO_InitStruct.Pin = EN11_Pin;
  GPIO_InitStruct.Mode = LL_GPIO_MODE_OUTPUT;
  GPIO_InitStruct.Speed = LL_GPIO_SPEED_FREQ_LOW;
  GPIO_InitStruct.OutputType = LL_GPIO_OUTPUT_PUSHPULL;
  GPIO_InitStruct.Pull = LL_GPIO_PULL_NO;
  LL_GPIO_Init(EN11_GPIO_Port, &GPIO_InitStruct);

  /**/
  GPIO_InitStruct.Pin = EN12_Pin;
  GPIO_InitStruct.Mode = LL_GPIO_MODE_OUTPUT;
  GPIO_InitStruct.Speed = LL_GPIO_SPEED_FREQ_LOW;
  GPIO_InitStruct.OutputType = LL_GPIO_OUTPUT_PUSHPULL;
  GPIO_InitStruct.Pull = LL_GPIO_PULL_NO;
  LL_GPIO_Init(EN12_GPIO_Port, &GPIO_InitStruct);

  /**/
  GPIO_InitStruct.Pin = EN13_Pin;
  GPIO_InitStruct.Mode = LL_GPIO_MODE_OUTPUT;
  GPIO_InitStruct.Speed = LL_GPIO_SPEED_FREQ_LOW;
  GPIO_InitStruct.OutputType = LL_GPIO_OUTPUT_PUSHPULL;
  GPIO_InitStruct.Pull = LL_GPIO_PULL_NO;
  LL_GPIO_Init(EN13_GPIO_Port, &GPIO_InitStruct);

  /**/
  GPIO_InitStruct.Pin = EN14_Pin;
  GPIO_InitStruct.Mode = LL_GPIO_MODE_OUTPUT;
  GPIO_InitStruct.Speed = LL_GPIO_SPEED_FREQ_LOW;
  GPIO_InitStruct.OutputType = LL_GPIO_OUTPUT_PUSHPULL;
  GPIO_InitStruct.Pull = LL_GPIO_PULL_NO;
  LL_GPIO_Init(EN14_GPIO_Port, &GPIO_InitStruct);

  /**/
  GPIO_InitStruct.Pin = EN15_Pin;
  GPIO_InitStruct.Mode = LL_GPIO_MODE_OUTPUT;
  GPIO_InitStruct.Speed = LL_GPIO_SPEED_FREQ_LOW;
  GPIO_InitStruct.OutputType = LL_GPIO_OUTPUT_PUSHPULL;
  GPIO_InitStruct.Pull = LL_GPIO_PULL_NO;
  LL_GPIO_Init(EN15_GPIO_Port, &GPIO_InitStruct);

  /**/
  GPIO_InitStruct.Pin = EN16_Pin;
  GPIO_InitStruct.Mode = LL_GPIO_MODE_OUTPUT;
  GPIO_InitStruct.Speed = LL_GPIO_SPEED_FREQ_LOW;
  GPIO_InitStruct.OutputType = LL_GPIO_OUTPUT_PUSHPULL;
  GPIO_InitStruct.Pull = LL_GPIO_PULL_NO;
  LL_GPIO_Init(EN16_GPIO_Port, &GPIO_InitStruct);

  /**/
  GPIO_InitStruct.Pin = EN17_Pin;
  GPIO_InitStruct.Mode = LL_GPIO_MODE_OUTPUT;
  GPIO_InitStruct.Speed = LL_GPIO_SPEED_FREQ_LOW;
  GPIO_InitStruct.OutputType = LL_GPIO_OUTPUT_PUSHPULL;
  GPIO_InitStruct.Pull = LL_GPIO_PULL_NO;
  LL_GPIO_Init(EN17_GPIO_Port, &GPIO_InitStruct);

  /**/
  GPIO_InitStruct.Pin = EN18_Pin;
  GPIO_InitStruct.Mode = LL_GPIO_MODE_OUTPUT;
  GPIO_InitStruct.Speed = LL_GPIO_SPEED_FREQ_LOW;
  GPIO_InitStruct.OutputType = LL_GPIO_OUTPUT_PUSHPULL;
  GPIO_InitStruct.Pull = LL_GPIO_PULL_NO;
  LL_GPIO_Init(EN18_GPIO_Port, &GPIO_InitStruct);

  /**/
  GPIO_InitStruct.Pin = EN19_Pin;
  GPIO_InitStruct.Mode = LL_GPIO_MODE_OUTPUT;
  GPIO_InitStruct.Speed = LL_GPIO_SPEED_FREQ_LOW;
  GPIO_InitStruct.OutputType = LL_GPIO_OUTPUT_PUSHPULL;
  GPIO_InitStruct.Pull = LL_GPIO_PULL_NO;
  LL_GPIO_Init(EN19_GPIO_Port, &GPIO_InitStruct);

  /**/
  GPIO_InitStruct.Pin = EN20_Pin;
  GPIO_InitStruct.Mode = LL_GPIO_MODE_OUTPUT;
  GPIO_InitStruct.Speed = LL_GPIO_SPEED_FREQ_LOW;
  GPIO_InitStruct.OutputType = LL_GPIO_OUTPUT_PUSHPULL;
  GPIO_InitStruct.Pull = LL_GPIO_PULL_NO;
  LL_GPIO_Init(EN20_GPIO_Port, &GPIO_InitStruct);

  /**/
  GPIO_InitStruct.Pin = EN21_Pin;
  GPIO_InitStruct.Mode = LL_GPIO_MODE_OUTPUT;
  GPIO_InitStruct.Speed = LL_GPIO_SPEED_FREQ_LOW;
  GPIO_InitStruct.OutputType = LL_GPIO_OUTPUT_PUSHPULL;
  GPIO_InitStruct.Pull = LL_GPIO_PULL_NO;
  LL_GPIO_Init(EN21_GPIO_Port, &GPIO_InitStruct);

  /**/
  GPIO_InitStruct.Pin = EN22_Pin;
  GPIO_InitStruct.Mode = LL_GPIO_MODE_OUTPUT;
  GPIO_InitStruct.Speed = LL_GPIO_SPEED_FREQ_LOW;
  GPIO_InitStruct.OutputType = LL_GPIO_OUTPUT_PUSHPULL;
  GPIO_InitStruct.Pull = LL_GPIO_PULL_NO;
  LL_GPIO_Init(EN22_GPIO_Port, &GPIO_InitStruct);

  /**/
  GPIO_InitStruct.Pin = EN23_Pin;
  GPIO_InitStruct.Mode = LL_GPIO_MODE_OUTPUT;
  GPIO_InitStruct.Speed = LL_GPIO_SPEED_FREQ_LOW;
  GPIO_InitStruct.OutputType = LL_GPIO_OUTPUT_PUSHPULL;
  GPIO_InitStruct.Pull = LL_GPIO_PULL_NO;
  LL_GPIO_Init(EN23_GPIO_Port, &GPIO_InitStruct);

  /**/
  GPIO_InitStruct.Pin = EN24_Pin;
  GPIO_InitStruct.Mode = LL_GPIO_MODE_OUTPUT;
  GPIO_InitStruct.Speed = LL_GPIO_SPEED_FREQ_LOW;
  GPIO_InitStruct.OutputType = LL_GPIO_OUTPUT_PUSHPULL;
  GPIO_InitStruct.Pull = LL_GPIO_PULL_NO;
  LL_GPIO_Init(EN24_GPIO_Port, &GPIO_InitStruct);

  /**/
  GPIO_InitStruct.Pin = D_CLR_Pin;
  GPIO_InitStruct.Mode = LL_GPIO_MODE_OUTPUT;
  GPIO_InitStruct.Speed = LL_GPIO_SPEED_FREQ_LOW;
  GPIO_InitStruct.OutputType = LL_GPIO_OUTPUT_PUSHPULL;
  GPIO_InitStruct.Pull = LL_GPIO_PULL_NO;
  LL_GPIO_Init(D_CLR_GPIO_Port, &GPIO_InitStruct);

  /**/
  GPIO_InitStruct.Pin = EN_1_2V_Pin;
  GPIO_InitStruct.Mode = LL_GPIO_MODE_OUTPUT;
  GPIO_InitStruct.Speed = LL_GPIO_SPEED_FREQ_LOW;
  GPIO_InitStruct.OutputType = LL_GPIO_OUTPUT_PUSHPULL;
  GPIO_InitStruct.Pull = LL_GPIO_PULL_NO;
  LL_GPIO_Init(EN_1_2V_GPIO_Port, &GPIO_InitStruct);

}

/* USER CODE BEGIN 4 */

void Activate_ADC(ADC_TypeDef *ADCx)
{
  __IO uint32_t wait_loop_index = 0U;
  #if (USE_TIMEOUT == 1)
  uint32_t Timeout = 0U; /* Variable used for timeout management */
  #endif /* USE_TIMEOUT */

  /*## Operation on ADC hierarchical scope: ADC instance #####################*/

  /* Note: Hardware constraint (refer to description of the functions         */
  /*       below):                                                            */
  /*       On this STM32 series, setting of these features is conditioned to   */
  /*       ADC state:                                                         */
  /*       ADC must be disabled.                                              */
  /* Note: In this example, all these checks are not necessary but are        */
  /*       implemented anyway to show the best practice usages                */
  /*       corresponding to reference manual procedure.                       */
  /*       Software can be optimized by removing some of these checks, if     */
  /*       they are not relevant considering previous settings and actions    */
  /*       in user application.                                               */
  if (LL_ADC_IsEnabled(ADCx) == 0)
  {
    /* Disable ADC deep power down (enabled by default after reset state) */
    LL_ADC_DisableDeepPowerDown(ADCx);

    /* Enable ADC internal voltage regulator */
    LL_ADC_EnableInternalRegulator(ADCx);

    /* Delay for ADC internal voltage regulator stabilization.                */
    /* Compute number of CPU cycles to wait for, from delay in us.            */
    /* Note: Variable divided by 2 to compensate partially                    */
    /*       CPU processing cycles (depends on compilation optimization).     */
    /* Note: If system core clock frequency is below 200kHz, wait time        */
    /*       is only a few CPU processing cycles.                             */
    wait_loop_index = ((LL_ADC_DELAY_INTERNAL_REGUL_STAB_US * (SystemCoreClock / (100000 * 2))) / 10);   //  20* 170000000/200000/10
    while(wait_loop_index != 0)
    {
      wait_loop_index--;
    }

    /* Run ADC self calibration */
    LL_ADC_StartCalibration(ADCx, LL_ADC_SINGLE_ENDED);

		delayms(10);
    while (LL_ADC_IsCalibrationOnGoing(ADCx) != 0)
    {

    }

    /* Delay between ADC end of calibration and ADC enable.                   */
    /* Note: Variable divided by 2 to compensate partially                    */
    /*       CPU processing cycles (depends on compilation optimization).     */
		delayms(20);

    /* Enable ADC */
    LL_ADC_Enable(ADCx);

    /* Poll for ADC ready to convert */
		delayms(20);

    while (LL_ADC_IsActiveFlag_ADRDY(ADCx) == 0)
    {

    }

    /* Note: ADC flag ADRDY is not cleared here to be able to check ADC       */
    /*       status afterwards.                                               */
    /*       This flag should be cleared at ADC Deactivation, before a new    */
    /*       ADC activation, using function "LL_ADC_ClearFlag_ADRDY()".       */
  }

}
/* USER CODE END 4 */

void Error_Handler(void)
{
  __disable_irq();
  while (1)
  {
  }
}
